VERSION "dbc-export 1 2026.26.6.5"

NS_ :

BS_:

BU_: ADSP APB APP APS APSB BB BMS CC CMP CMPD CP DAS DI DIF DIR DPB EPAS3P EPAS3S EPASTP EPASTS EPBL EPBR ESP EVSE FC GTW HCML HCMR HVP IBST ICR IDB LS OCS1P ODIN PARK PCS PCS2 PLG PM PMF PMR PNCD PTC RADC RCM RCM2 RCM3 RCU SCCM SCM SCS SDCR TAS TCU TCU2 TPMS TRCM UDS UI UIS UMC USM V2G VC VCBATT VCBATT0 VCBATT1 VCBATT2 VCCC VCFRONT VCFRONT1 VCFRONT2 VCLEFT VCRIGHT VCSEAT2L VCSEAT2R VCSEC VEH

BO_ 601 APP_status: 8 APP
 SG_ APP_watchdogState : 0|3@1+ (1,0) [0|6] "" Vector__XXX
 SG_ APP_fusedState : 3|2@1+ (1,0) [0|2] "" Vector__XXX
 SG_ APP_cameraHeaterRequest : 5|1@1+ (1,0) [0|1] "" Vector__XXX
 SG_ APP_factorySummonStatus : 6|4@1+ (1,0) [1|15] "" Vector__XXX
 SG_ APP_clipRecordingStatus : 10|3@1+ (1,0) [0|7] "" Vector__XXX
 SG_ APP_allowApActivationWithBrake : 13|1@1+ (1,0) [0|1] "" Vector__XXX
 SG_ APP_summonUnavailableReason : 14|5@1+ (1,0) [0|31] "" Vector__XXX
 SG_ APP_fsdSuspendState : 19|2@1+ (1,0) [0|2] "" Vector__XXX
 SG_ APP_fsdRevokeStrikeoutCount : 21|3@1+ (1,0) [0|6] "" Vector__XXX
 SG_ APP_teslaVisionSupported : 24|2@1+ (1,0) [0|2] "" Vector__XXX
 SG_ APP_teslaVisionUnsupportedReason : 26|3@1+ (1,0) [0|7] "" Vector__XXX
 SG_ APP_fsdRevokeCount : 29|3@1+ (1,0) [0|6] "" Vector__XXX
 SG_ APP_excessiveAccelPedalWarning : 32|1@1+ (1,0) [0|1] "" Vector__XXX
 SG_ APP_unifiedObjectStackSupported : 33|2@1+ (1,0) [0|2] "" Vector__XXX
 SG_ APP_sendingBUCStream : 35|1@1+ (1,0) [0|1] "" Vector__XXX
 SG_ APP_DDAWSystemStatus : 37|3@1+ (1,0) [0|7] "" Vector__XXX
 SG_ APP_socOperatingMode : 40|2@1+ (1,0) [0|3] "" Vector__XXX
 SG_ APP_summonVersionIdentifier : 42|2@1+ (1,0) [0|3] "" Vector__XXX
 SG_ APP_sentryState : 44|3@1+ (1,0) [0|7] "" Vector__XXX
 SG_ APP_autoparkVersionIdentifier : 47|2@1+ (1,0) [0|3] "" Vector__XXX
 SG_ APP_autonomySystemHealth : 49|1@1+ (1,0) [0|1] "" Vector__XXX
 SG_ APP_uiEthFailoverDisabled : 50|1@1+ (1,0) [0|1] "" Vector__XXX
 SG_ APP_suspendResumeAvailable : 51|1@1+ (1,0) [0|1] "" Vector__XXX
 SG_ APP_statusCounter : 52|4@1+ (1,0) [0|15] "" Vector__XXX
 SG_ APP_statusChecksum : 56|8@1+ (1,0) [0|255] "" Vector__XXX

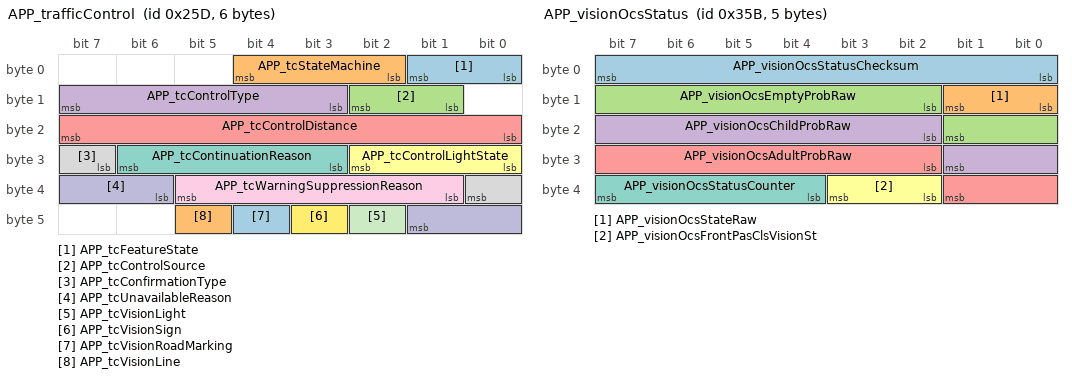
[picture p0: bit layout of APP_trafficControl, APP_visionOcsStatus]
BO_ 605 APP_trafficControl: 6 APP
 SG_ APP_tcFeatureState : 0|2@1+ (1,0) [0|3] "" Vector__XXX
 SG_ APP_tcStateMachine : 2|3@1+ (1,0) [0|7] "" Vector__XXX
 SG_ APP_tcControlSource : 9|2@1+ (1,0) [0|3] "" Vector__XXX
 SG_ APP_tcControlType : 11|5@1+ (1,0) [0|31] "" Vector__XXX
 SG_ APP_tcControlDistance : 16|8@1+ (1,0) [0|254] "m" Vector__XXX
 SG_ APP_tcControlLightState : 24|3@1+ (1,0) [0|7] "" Vector__XXX
 SG_ APP_tcContinuationReason : 27|4@1+ (1,0) [0|15] "" Vector__XXX
 SG_ APP_tcConfirmationType : 31|2@1+ (1,0) [0|3] "" Vector__XXX
 SG_ APP_tcWarningSuppressionReason : 33|5@1+ (1,0) [0|31] "" Vector__XXX
 SG_ APP_tcUnavailableReason : 38|4@1+ (1,0) [0|15] "" Vector__XXX
 SG_ APP_tcVisionLight : 42|1@1+ (1,0) [0|1] "" Vector__XXX
 SG_ APP_tcVisionSign : 43|1@1+ (1,0) [0|1] "" Vector__XXX
 SG_ APP_tcVisionRoadMarking : 44|1@1+ (1,0) [0|1] "" Vector__XXX
 SG_ APP_tcVisionLine : 45|1@1+ (1,0) [0|1] "" Vector__XXX

BO_ 859 APP_visionOcsStatus: 5 APP
 SG_ APP_visionOcsStatusChecksum : 0|8@1+ (1,0) [0|255] "" Vector__XXX
 SG_ APP_visionOcsStateRaw : 8|2@1+ (1,0) [0|3] "" Vector__XXX
 SG_ APP_visionOcsEmptyProbRaw : 10|8@1+ (0.004,0) [0|1.016] "points" Vector__XXX
 SG_ APP_visionOcsChildProbRaw : 18|8@1+ (0.004,0) [0|1.016] "points" Vector__XXX
 SG_ APP_visionOcsAdultProbRaw : 26|8@1+ (0.004,0) [0|1.016] "points" Vector__XXX
 SG_ APP_visionOcsFrontPasClsVisionSt : 34|2@1+ (1,0) [0|3] "" Vector__XXX
 SG_ APP_visionOcsStatusCounter : 36|4@1+ (1,0) [0|15] "" Vector__XXX

BO_ 809 APP_warningMatrix0: 8 APP
 SG_ APP_w001_DEPRECATED : 0|1@1+ (1,0) [0|1] "" Vector__XXX
 SG_ APP_w002_ldwDisabled : 1|1@1+ (1,0) [0|1] "" Vector__XXX
 SG_ APP_w003_isaDisabled : 2|1@1+ (1,0) [0|1] "" Vector__XXX
 SG_ APP_w004_accDisabled : 3|1@1+ (1,0) [0|1] "" Vector__XXX
 SG_ APP_w005_fcwCancelled : 4|1@1+ (1,0) [0|1] "" Vector__XXX
 SG_ APP_w006_aebCancelled : 5|1@1+ (1,0) [0|1] "" Vector__XXX
 SG_ APP_w007_ahlbDisabled : 6|1@1+ (1,0) [0|1] "" Vector__XXX
 SG_ APP_w008_parkDisabled : 7|1@1+ (1,0) [0|1] "" Vector__XXX
 SG_ APP_w009_aebFault : 8|1@1+ (1,0) [0|1] "" Vector__XXX
 SG_ APP_w010_radcCalibIssue : 9|1@1+ (1,0) [0|1] "" Vector__XXX
 SG_ APP_w011_scaEvent : 10|1@1+ (1,0) [0|1] "" Vector__XXX
 SG_ APP_w012_Cam_BootFailure : 11|1@1+ (1,0) [0|1] "" Vector__XXX
 SG_ APP_w013_Cam_Watchdog : 12|1@1+ (1,0) [0|1] "" Vector__XXX
 SG_ APP_w014_swAssert : 13|1@1+ (1,0) [0|1] "" Vector__XXX
 SG_ APP_w015_Camera_Failsafes : 14|1@1+ (1,0) [0|1] "" Vector__XXX
 SG_ APP_w016_aeb_e_event : 15|1@1+ (1,0) [0|1] "" Vector__XXX
 SG_ APP_w017_Cam_Msg_MIA : 16|1@1+ (1,0) [0|1] "" Vector__XXX
 SG_ APP_w018_ECU_Power_Issue : 17|1@1+ (1,0) [0|1] "" Vector__XXX
 SG_ APP_w019_ECU_Stack_Overflow : 18|1@1+ (1,0) [0|1] "" Vector__XXX
 SG_ APP_w020_ECU_checkstopError : 19|1@1+ (1,0) [0|1] "" Vector__XXX
 SG_ APP_w021_ECU_Temperature_Issue : 20|1@1+ (1,0) [0|1] "" Vector__XXX
 SG_ APP_w022_ECU_EEPROM_Failure : 21|1@1+ (1,0) [0|1] "" Vector__XXX
 SG_ APP_w023_ECU_Cam_Statemismatc : 22|1@1+ (1,0) [0|1] "" Vector__XXX
 SG_ APP_w024_ECU_Watchdog_Reset : 23|1@1+ (1,0) [0|1] "" Vector__XXX
 SG_ APP_w025_LC_Steering_Override : 24|1@1+ (1,0) [0|1] "" Vector__XXX
 SG_ APP_w026_ECU_timingIssue : 25|1@1+ (1,0) [0|1] "" Vector__XXX
 SG_ APP_w027_ECU_Reset_Fault : 26|1@1+ (1,0) [0|1] "" Vector__XXX
 SG_ APP_w028_spi_rx_error : 27|1@1+ (1,0) [0|1] "" Vector__XXX
 SG_ APP_w029_spi_tx_error : 28|1@1+ (1,0) [0|1] "" Vector__XXX
 SG_ APP_w030_Heater_Issue : 29|1@1+ (1,0) [0|1] "" Vector__XXX
 SG_ APP_w031_canRxError : 30|1@1+ (1,0) [0|1] "" Vector__XXX
 SG_ APP_w032_canTxError : 31|1@1+ (1,0) [0|1] "" Vector__XXX
 SG_ APP_w033_gtwMia : 32|1@1+ (1,0) [0|1] "" Vector__XXX
 SG_ APP_w034_sccmMia : 33|1@1+ (1,0) [0|1] "" Vector__XXX
 SG_ APP_w035_espMia : 34|1@1+ (1,0) [0|1] "" Vector__XXX
 SG_ APP_w036_bdyMia : 35|1@1+ (1,0) [0|1] "" Vector__XXX
 SG_ APP_w037_camTacIssue : 36|1@1+ (1,0) [0|1] "" Vector__XXX
 SG_ APP_w038_camFailure : 37|1@1+ (1,0) [0|1] "" Vector__XXX
 SG_ APP_w039_sdm_rcm_Mia : 38|1@1+ (1,0) [0|1] "" Vector__XXX
 SG_ APP_w040_autopilotAngleSaturated : 39|1@1+ (1,0) [0|1] "" Vector__XXX
 SG_ APP_w041_autopilotRateSaturated : 40|1@1+ (1,0) [0|1] "" Vector__XXX
 SG_ APP_w042_autopilotAborting : 41|1@1+ (1,0) [0|1] "" Vector__XXX
 SG_ APP_w043_camLongRunTime : 42|1@1+ (1,0) [0|1] "" Vector__XXX
 SG_ APP_w044_appMobileyeFailure : 43|1@1+ (1,0) [0|1] "" Vector__XXX
 SG_ APP_w045_radMia : 44|1@1+ (1,0) [0|1] "" Vector__XXX
 SG_ APP_w046_eepromRecordAbsent : 45|1@1+ (1,0) [0|1] "" Vector__XXX
 SG_ APP_w047_edrEvent : 46|1@1+ (1,0) [0|1] "" Vector__XXX
 SG_ APP_w048_APP_Features_Disabled : 47|1@1+ (1,0) [0|1] "" Vector__XXX
 SG_ APP_w049_eyeqVersionMismatch : 48|1@1+ (1,0) [0|1] "" Vector__XXX
 SG_ APP_w050_aeb_event : 49|1@1+ (1,0) [0|1] "" Vector__XXX
 SG_ APP_w051_radcEcuIssue : 50|1@1+ (1,0) [0|1] "" Vector__XXX
 SG_ APP_w052_radcSensorIssue : 51|1@1+ (1,0) [0|1] "" Vector__XXX
 SG_ APP_w053_radcCommIssue : 52|1@1+ (1,0) [0|1] "" Vector__XXX
 SG_ APP_w054_camAutofix : 53|1@1+ (1,0) [0|1] "" Vector__XXX
 SG_ APP_w055_radcVersionMismatch : 54|1@1+ (1,0) [0|1] "" Vector__XXX
 SG_ APP_w056_diMia : 55|1@1+ (1,0) [0|1] "" Vector__XXX
 SG_ APP_w057_mcuMia : 56|1@1+ (1,0) [0|1] "" Vector__XXX
 SG_ APP_w058_epbMia : 57|1@1+ (1,0) [0|1] "" Vector__XXX
 SG_ APP_w059_parkMia : 58|1@1+ (1,0) [0|1] "" Vector__XXX
 SG_ APP_w060_fcw_event : 59|1@1+ (1,0) [0|1] "" Vector__XXX
 SG_ APP_w061_airSuspensionMia : 60|1@1+ (1,0) [0|1] "" Vector__XXX
 SG_ APP_w062_radcAlignment : 61|1@1+ (1,0) [0|1] "" Vector__XXX
 SG_ APP_w063_parkVersionMismatch : 62|1@1+ (1,0) [0|1] "" Vector__XXX
 SG_ APP_w064_epasMia : 63|1@1+ (1,0) [0|1] "" Vector__XXX

BO_ 873 APP_warningMatrix1: 8 APP
 SG_ APP_w065_deserializerOvercurrent : 0|1@1+ (1,0) [0|1] "" Vector__XXX
 SG_ APP_w066_deserializerLockLost : 1|1@1+ (1,0) [0|1] "" Vector__XXX
 SG_ APP_w067_steeringAlignment : 2|1@1+ (1,0) [0|1] "" Vector__XXX
 SG_ APP_w068_vlInconsistency : 3|1@1+ (1,0) [0|1] "" Vector__XXX
 SG_ APP_w069_apcSpaceMasked : 4|1@1+ (1,0) [0|1] "" Vector__XXX
 SG_ APP_w070_apcIncompleteCal : 5|1@1+ (1,0) [0|1] "" Vector__XXX
 SG_ APP_w071_selfparkStarted : 6|1@1+ (1,0) [0|1] "" Vector__XXX
 SG_ APP_w072_selfparkComplete : 7|1@1+ (1,0) [0|1] "" Vector__XXX
 SG_ APP_w073_issueEscalatedLDW : 8|1@1+ (1,0) [0|1] "" Vector__XXX
 SG_ APP_w074_inPathStationaryObst : 9|1@1+ (1,0) [0|1] "" Vector__XXX
 SG_ APP_w075_scMia : 10|1@1+ (1,0) [0|1] "" Vector__XXX
 SG_ APP_w076_mobilEyeSetC : 11|1@1+ (1,0) [0|1] "" Vector__XXX
 SG_ APP_w077_pmmActive : 12|1@1+ (1,0) [0|1] "" Vector__XXX
 SG_ APP_w078_pmmActive2 : 13|1@1+ (1,0) [0|1] "" Vector__XXX
 SG_ APP_w079_edrAvailable : 14|1@1+ (1,0) [0|1] "" Vector__XXX
 SG_ APP_w080_accFailedActivation : 15|1@1+ (1,0) [0|1] "" Vector__XXX
 SG_ APP_w081_pmmActiveBraking : 16|1@1+ (1,0) [0|1] "" Vector__XXX
 SG_ APP_w082_inPathFSviolation : 17|1@1+ (1,0) [0|1] "" Vector__XXX
 SG_ APP_w083_inPathRADObject : 18|1@1+ (1,0) [0|1] "" Vector__XXX
 SG_ APP_w084_pmmIPSO : 19|1@1+ (1,0) [0|1] "" Vector__XXX
 SG_ APP_w085_pmmSteering : 20|1@1+ (1,0) [0|1] "" Vector__XXX
 SG_ APP_w086_robCollision : 21|1@1+ (1,0) [0|1] "" Vector__XXX
 SG_ APP_w087_DEPRECATED : 22|1@1+ (1,0) [0|1] "" Vector__XXX
 SG_ APP_w088_DEPRECATED : 23|1@1+ (1,0) [0|1] "" Vector__XXX
 SG_ APP_w089_DEPRECATED : 24|1@1+ (1,0) [0|1] "" Vector__XXX
 SG_ APP_w090_DEPRECATED : 25|1@1+ (1,0) [0|1] "" Vector__XXX
 SG_ APP_w091_DEPRECATED : 26|1@1+ (1,0) [0|1] "" Vector__XXX
 SG_ APP_w092_DEPRECATED : 27|1@1+ (1,0) [0|1] "" Vector__XXX
 SG_ APP_w093_DEPRECATED : 28|1@1+ (1,0) [0|1] "" Vector__XXX
 SG_ APP_w094_DEPRECATED : 29|1@1+ (1,0) [0|1] "" Vector__XXX
 SG_ APP_w095_DEPRECATED : 30|1@1+ (1,0) [0|1] "" Vector__XXX
 SG_ APP_w096_DEPRECATED : 31|1@1+ (1,0) [0|1] "" Vector__XXX
 SG_ APP_w097_DEPRECATED : 32|1@1+ (1,0) [0|1] "" Vector__XXX
 SG_ APP_w098_DEPRECATED : 33|1@1+ (1,0) [0|1] "" Vector__XXX
 SG_ APP_w099_DEPRECATED : 34|1@1+ (1,0) [0|1] "" Vector__XXX
 SG_ APP_w100_DEPRECATED : 35|1@1+ (1,0) [0|1] "" Vector__XXX
 SG_ APP_w101_DEPRECATED : 36|1@1+ (1,0) [0|1] "" Vector__XXX
 SG_ APP_w102_DEPRECATED : 37|1@1+ (1,0) [0|1] "" Vector__XXX
 SG_ APP_w103_robExperimentalAEB : 38|1@1+ (1,0) [0|1] "" Vector__XXX
 SG_ APP_w104_DEPRECATED : 39|1@1+ (1,0) [0|1] "" Vector__XXX
 SG_ APP_w105_DEPRECATED : 40|1@1+ (1,0) [0|1] "" Vector__XXX
 SG_ APP_w106_torsionBarOffset : 41|1@1+ (1,0) [0|1] "" Vector__XXX

BO_ 1065 APP_warningMatrix2: 8 APP
 SG_ APP_w129_mainCamExtNotCal : 0|1@1+ (1,0) [0|1] "" Vector__XXX
 SG_ APP_w130_narrowCamExtNotCal : 1|1@1+ (1,0) [0|1] "" Vector__XXX
 SG_ APP_w131_mainCamCalSaved : 2|1@1+ (1,0) [0|1] "" Vector__XXX
 SG_ APP_w132_narrowCamCalSaved : 3|1@1+ (1,0) [0|1] "" Vector__XXX
 SG_ APP_w133_mainCamInitFault : 4|1@1+ (1,0) [0|1] "" Vector__XXX
 SG_ APP_w134_narrowCamInitFault : 5|1@1+ (1,0) [0|1] "" Vector__XXX
 SG_ APP_w135_fisheyeCamInitFault : 6|1@1+ (1,0) [0|1] "" Vector__XXX
 SG_ APP_w136_lPillarCamInitFault : 7|1@1+ (1,0) [0|1] "" Vector__XXX
 SG_ APP_w137_rPillarCamInitFault : 8|1@1+ (1,0) [0|1] "" Vector__XXX
 SG_ APP_w138_lRepeatCamInitFault : 9|1@1+ (1,0) [0|1] "" Vector__XXX
 SG_ APP_w139_rRepeatCamInitFault : 10|1@1+ (1,0) [0|1] "" Vector__XXX
 SG_ APP_w140_backupCamInitFault : 11|1@1+ (1,0) [0|1] "" Vector__XXX
 SG_ APP_w141_ECU_Thermal_Issue : 12|1@1+ (1,0) [0|1] "" Vector__XXX
 SG_ APP_w142_fwdCamPitchProblem : 13|1@1+ (1,0) [0|1] "" Vector__XXX
 SG_ APP_w143_IDF_event : 14|1@1+ (1,0) [0|1] "" Vector__XXX
 SG_ APP_w144_fanctrldError : 15|1@1+ (1,0) [0|1] "" Vector__XXX
 SG_ APP_w145_camSelfCalIssue : 16|1@1+ (1,0) [0|1] "" Vector__XXX
 SG_ APP_w146_telemetryProblem : 17|1@1+ (1,0) [0|1] "" Vector__XXX
 SG_ APP_w147_selfieCamInitFault : 18|1@1+ (1,0) [0|1] "" Vector__XXX
 SG_ APP_w148_overlayActive : 19|1@1+ (1,0) [0|1] "" Vector__XXX
 SG_ APP_w149_diskFull : 20|1@1+ (1,0) [0|1] "" Vector__XXX
 SG_ APP_w150_diMiaPartyBus : 21|1@1+ (1,0) [0|1] "" Vector__XXX
 SG_ APP_w151_epasMiaPartyBus : 22|1@1+ (1,0) [0|1] "" Vector__XXX
 SG_ APP_w152_espMiaPartyBus : 23|1@1+ (1,0) [0|1] "" Vector__XXX
 SG_ APP_w153_rcmMiaPartyBus : 24|1@1+ (1,0) [0|1] "" Vector__XXX
 SG_ APP_w154_vcleftMiaPartyBus : 25|1@1+ (1,0) [0|1] "" Vector__XXX
 SG_ APP_w155_vcrightMiaPartyBus : 26|1@1+ (1,0) [0|1] "" Vector__XXX
 SG_ APP_w156_epblMiaVehBus : 27|1@1+ (1,0) [0|1] "" Vector__XXX
 SG_ APP_w157_sccmMiaVehBus : 28|1@1+ (1,0) [0|1] "" Vector__XXX
 SG_ APP_w158_vcfrontMiaVehBus : 29|1@1+ (1,0) [0|1] "" Vector__XXX
 SG_ APP_w159_vcleftMiaVehBus : 30|1@1+ (1,0) [0|1] "" Vector__XXX
 SG_ APP_w160_vcrightMiaVehBus : 31|1@1+ (1,0) [0|1] "" Vector__XXX
 SG_ APP_w161_backupCameraUnavailable : 32|1@1+ (1,0) [0|1] "" Vector__XXX
 SG_ APP_w162_mainCameraTypeError : 33|1@1+ (1,0) [0|1] "" Vector__XXX
 SG_ APP_w163_narrowCameraTypeError : 34|1@1+ (1,0) [0|1] "" Vector__XXX
 SG_ APP_w164_fisheyeCameraTypeError : 35|1@1+ (1,0) [0|1] "" Vector__XXX
 SG_ APP_w165_lPillarCameraTypeError : 36|1@1+ (1,0) [0|1] "" Vector__XXX
 SG_ APP_w166_rPillarCameraTypeError : 37|1@1+ (1,0) [0|1] "" Vector__XXX
 SG_ APP_w167_lRepeatCameraTypeError : 38|1@1+ (1,0) [0|1] "" Vector__XXX
 SG_ APP_w168_rRepeatCameraTypeError : 39|1@1+ (1,0) [0|1] "" Vector__XXX
 SG_ APP_w169_backupCameraTypeError : 40|1@1+ (1,0) [0|1] "" Vector__XXX
 SG_ APP_w170_selfieCameraTypeError : 41|1@1+ (1,0) [0|1] "" Vector__XXX
 SG_ APP_w171_appHighCoolantFlowReq : 42|1@1+ (1,0) [0|1] "" Vector__XXX
 SG_ APP_w172_fisheyeCamExtNotCal : 43|1@1+ (1,0) [0|1] "" Vector__XXX
 SG_ APP_w173_lPillarCamExtNotCal : 44|1@1+ (1,0) [0|1] "" Vector__XXX
 SG_ APP_w174_rPillarCamExtNotCal : 45|1@1+ (1,0) [0|1] "" Vector__XXX
 SG_ APP_w175_lRepeatCamExtNotCal : 46|1@1+ (1,0) [0|1] "" Vector__XXX
 SG_ APP_w176_rRepeatCamExtNotCal : 47|1@1+ (1,0) [0|1] "" Vector__XXX
 SG_ APP_w177_fisheyeCamCalSaved : 48|1@1+ (1,0) [0|1] "" Vector__XXX
 SG_ APP_w178_lPillarCamCalSaved : 49|1@1+ (1,0) [0|1] "" Vector__XXX
 SG_ APP_w179_rPillarCamCalSaved : 50|1@1+ (1,0) [0|1] "" Vector__XXX
 SG_ APP_w180_lRepeatCamCalSaved : 51|1@1+ (1,0) [0|1] "" Vector__XXX
 SG_ APP_w181_rRepeatCamCalSaved : 52|1@1+ (1,0) [0|1] "" Vector__XXX
 SG_ APP_w182_mainCameraStreamExit : 53|1@1+ (1,0) [0|1] "" Vector__XXX
 SG_ APP_w183_narrowCameraStreamExit : 54|1@1+ (1,0) [0|1] "" Vector__XXX
 SG_ APP_w184_fisheyeCameraStreamExit : 55|1@1+ (1,0) [0|1] "" Vector__XXX
 SG_ APP_w185_lPillarCameraStreamExit : 56|1@1+ (1,0) [0|1] "" Vector__XXX
 SG_ APP_w186_rPillarCameraStreamExit : 57|1@1+ (1,0) [0|1] "" Vector__XXX
 SG_ APP_w187_lRepeatCameraStreamExit : 58|1@1+ (1,0) [0|1] "" Vector__XXX
 SG_ APP_w188_rRepeatCameraStreamExit : 59|1@1+ (1,0) [0|1] "" Vector__XXX
 SG_ APP_w189_backupCameraStreamExit : 60|1@1+ (1,0) [0|1] "" Vector__XXX
 SG_ APP_w190_selfieCameraStreamExit : 61|1@1+ (1,0) [0|1] "" Vector__XXX
 SG_ APP_w191_autopilotAborting : 62|1@1+ (1,0) [0|1] "" Vector__XXX
 SG_ APP_w192_emergencySpeakerFail : 63|1@1+ (1,0) [0|1] "" Vector__XXX

BO_ 1081 APP_warningMatrix3: 8 APP
 SG_ APP_w193_camWindshieldUnclean : 0|1@1+ (1,0) [0|1] "" Vector__XXX
 SG_ APP_w194_accDriverResumeRqrd : 1|1@1+ (1,0) [0|1] "" Vector__XXX
 SG_ APP_w195_scwUnavailable : 2|1@1+ (1,0) [0|1] "" Vector__XXX
 SG_ APP_w196_stopSignWarning : 3|1@1+ (1,0) [0|1] "" Vector__XXX
 SG_ APP_w197_redLightWarning : 4|1@1+ (1,0) [0|1] "" Vector__XXX
 SG_ APP_w198_tsrUnavailable : 5|1@1+ (1,0) [0|1] "" Vector__XXX
 SG_ APP_w199_apcAbort : 6|1@1+ (1,0) [0|1] "" Vector__XXX
 SG_ APP_w200_lcSlowdown : 7|1@1+ (1,0) [0|1] "" Vector__XXX
 SG_ APP_w201_lcAborting : 8|1@1+ (1,0) [0|1] "" Vector__XXX
 SG_ APP_w202_scwNoisyEnvironment : 9|1@1+ (1,0) [0|1] "" Vector__XXX
 SG_ APP_w203_apcActivation : 10|1@1+ (1,0) [0|1] "" Vector__XXX
 SG_ APP_w204_apcFinalFront : 11|1@1+ (1,0) [0|1] "" Vector__XXX
 SG_ APP_w205_apcFinalRear : 12|1@1+ (1,0) [0|1] "" Vector__XXX
 SG_ APP_w206_autosteerNotEnabled : 13|1@1+ (1,0) [0|1] "" Vector__XXX
 SG_ APP_w207_autosteerUnavailable : 14|1@1+ (1,0) [0|1] "" Vector__XXX
 SG_ APP_w208_rackDetected : 15|1@1+ (1,0) [0|1] "" Vector__XXX
 SG_ APP_w209_autoSummonRequest : 16|1@1+ (1,0) [0|1] "" Vector__XXX
 SG_ APP_w210_camObstrcted : 17|1@1+ (1,0) [0|1] "" Vector__XXX
 SG_ APP_w211_accNoSeatBelt : 18|1@1+ (1,0) [0|1] "" Vector__XXX
 SG_ APP_w212_lcUnavailableStrikeOut : 19|1@1+ (1,0) [0|1] "" Vector__XXX
 SG_ APP_w213_autosteerStruckOut : 20|1@1+ (1,0) [0|1] "" Vector__XXX
 SG_ APP_w214_driverNotIntracting : 21|1@1+ (1,0) [0|1] "" Vector__XXX
 SG_ APP_w215_contDriverNotIntracting : 22|1@1+ (1,0) [0|1] "" Vector__XXX
 SG_ APP_w216_driverOverriding : 23|1@1+ (1,0) [0|1] "" Vector__XXX
 SG_ APP_w217_lcUnavailableSpeeding : 24|1@1+ (1,0) [0|1] "" Vector__XXX
 SG_ APP_w218_lcSpeedExceededLimit : 25|1@1+ (1,0) [0|1] "" Vector__XXX
 SG_ APP_w219_lcTempUnavailableSpeed : 26|1@1+ (1,0) [0|1] "" Vector__XXX
 SG_ APP_w220_lcTempUnavailableRoad : 27|1@1+ (1,0) [0|1] "" Vector__XXX
 SG_ APP_w221_accRadarBlind : 28|1@1+ (1,0) [0|1] "" Vector__XXX
 SG_ APP_w222_accCameraBlind : 29|1@1+ (1,0) [0|1] "" Vector__XXX
 SG_ APP_w223_accObjectInPath : 30|1@1+ (1,0) [0|1] "" Vector__XXX
 SG_ APP_w224_accCameraCalibration : 31|1@1+ (1,0) [0|1] "" Vector__XXX
 SG_ APP_w225_lcDegradedVisSpeedLmt : 32|1@1+ (1,0) [0|1] "" Vector__XXX
 SG_ APP_w226_lcCamCalNeededSpeedLmt : 33|1@1+ (1,0) [0|1] "" Vector__XXX
 SG_ APP_w227_virtualWallBlocked : 34|1@1+ (1,0) [0|1] "" Vector__XXX
 SG_ APP_w228_DEPRECATED : 35|1@1+ (1,0) [0|1] "" Vector__XXX
 SG_ APP_w229_alcUltrasoundDamaged : 36|1@1+ (1,0) [0|1] "" Vector__XXX
 SG_ APP_w230_alcUltrasoundBlocked : 37|1@1+ (1,0) [0|1] "" Vector__XXX
 SG_ APP_w231_idfEvent : 38|1@1+ (1,0) [0|1] "" Vector__XXX
 SG_ APP_w232_laneChangeRequested : 39|1@1+ (1,0) [0|1] "" Vector__XXX
 SG_ APP_w233_fsdQuizRequired : 40|1@1+ (1,0) [0|1] "" Vector__XXX
 SG_ APP_w234_activeSafetyTelemetry : 41|1@1+ (1,0) [0|1] "" Vector__XXX
 SG_ APP_w235_fsdRegionNotAllowed : 42|1@1+ (1,0) [0|1] "" Vector__XXX

BO_ 1097 APP_warningMatrix4: 8 APP
 SG_ APP_w257_brakeJerkEvent : 0|1@1+ (1,0) [0|1] "" Vector__XXX
 SG_ APP_w258_aebEvent : 1|1@1+ (1,0) [0|1] "" Vector__XXX
 SG_ APP_w259_aebOverrideEvent : 2|1@1+ (1,0) [0|1] "" Vector__XXX
 SG_ APP_w260_collisionWarningEvent : 3|1@1+ (1,0) [0|1] "" Vector__XXX
 SG_ APP_w261_pcieHardwareErrors : 4|1@1+ (1,0) [0|1] "" Vector__XXX
 SG_ APP_w262_apeCalibMode : 5|1@1+ (1,0) [0|1] "" Vector__XXX
 SG_ APP_w263_lssAbort : 6|1@1+ (1,0) [0|1] "" Vector__XXX
 SG_ APP_w264_lssFault : 7|1@1+ (1,0) [0|1] "" Vector__XXX
 SG_ APP_w265_drvOnNavUnavailable : 8|1@1+ (1,0) [0|1] "" Vector__XXX
 SG_ APP_w266_visionScheduleFallback : 9|1@1+ (1,0) [0|1] "" Vector__XXX
 SG_ APP_w267_benchtopEcu : 10|1@1+ (1,0) [0|1] "" Vector__XXX
 SG_ APP_w268_backupCamExtNotCal : 11|1@1+ (1,0) [0|1] "" Vector__XXX
 SG_ APP_w269_autopilotLimited : 12|1@1+ (1,0) [0|1] "" Vector__XXX
 SG_ APP_w270_blindspotRestricted : 13|1@1+ (1,0) [0|1] "" Vector__XXX
 SG_ APP_w271_laneChangeAborted : 14|1@1+ (1,0) [0|1] "" Vector__XXX
 SG_ APP_w272_laneChangeUnavailable : 15|1@1+ (1,0) [0|1] "" Vector__XXX
 SG_ APP_w273_lssEvent : 16|1@1+ (1,0) [0|1] "" Vector__XXX
 SG_ APP_w274_mainCameraStreamErr : 17|1@1+ (1,0) [0|1] "" Vector__XXX
 SG_ APP_w275_narrowCameraStreamErr : 18|1@1+ (1,0) [0|1] "" Vector__XXX
 SG_ APP_w276_fisheyeCameraStreamErr : 19|1@1+ (1,0) [0|1] "" Vector__XXX
 SG_ APP_w277_lPillarCameraStreamErr : 20|1@1+ (1,0) [0|1] "" Vector__XXX
 SG_ APP_w278_rPillarCameraStreamErr : 21|1@1+ (1,0) [0|1] "" Vector__XXX
 SG_ APP_w279_lRepeatCameraStreamErr : 22|1@1+ (1,0) [0|1] "" Vector__XXX
 SG_ APP_w280_rRepeatCameraStreamErr : 23|1@1+ (1,0) [0|1] "" Vector__XXX
 SG_ APP_w281_backupCameraStreamErr : 24|1@1+ (1,0) [0|1] "" Vector__XXX
 SG_ APP_w282_selfieCameraStreamErr : 25|1@1+ (1,0) [0|1] "" Vector__XXX
 SG_ APP_w283_enhancedSummonAbort : 26|1@1+ (1,0) [0|1] "" Vector__XXX
 SG_ APP_w284_gpsAntennaDisconnected : 27|1@1+ (1,0) [0|1] "" Vector__XXX
 SG_ APP_w285_gpsFaultReset : 28|1@1+ (1,0) [0|1] "" Vector__XXX
 SG_ APP_w286_gpsComIssue : 29|1@1+ (1,0) [0|1] "" Vector__XXX
 SG_ APP_w287_gpsFusionStatus : 30|1@1+ (1,0) [0|1] "" Vector__XXX
 SG_ APP_w288_trafficLightWarning : 31|1@1+ (1,0) [0|1] "" Vector__XXX
 SG_ APP_w289_dramCorrEccErrors : 32|1@1+ (1,0) [0|1] "" Vector__XXX
 SG_ APP_w290_dramUncorrEccErrors : 33|1@1+ (1,0) [0|1] "" Vector__XXX
 SG_ APP_w291_stopSignWarning : 34|1@1+ (1,0) [0|1] "" Vector__XXX
 SG_ APP_w293_mainCameraSyncFailed : 36|1@1+ (1,0) [0|1] "" Vector__XXX
 SG_ APP_w294_narrowCameraSyncFailed : 37|1@1+ (1,0) [0|1] "" Vector__XXX
 SG_ APP_w295_fisheyeCameraSyncFailed : 38|1@1+ (1,0) [0|1] "" Vector__XXX
 SG_ APP_w296_lPillarCameraSyncFailed : 39|1@1+ (1,0) [0|1] "" Vector__XXX
 SG_ APP_w297_rPillarCameraSyncFailed : 40|1@1+ (1,0) [0|1] "" Vector__XXX
 SG_ APP_w298_lRepeatCameraSyncFailed : 41|1@1+ (1,0) [0|1] "" Vector__XXX
 SG_ APP_w299_rRepeatCameraSyncFailed : 42|1@1+ (1,0) [0|1] "" Vector__XXX
 SG_ APP_w300_backupCameraSyncFailed : 43|1@1+ (1,0) [0|1] "" Vector__XXX
 SG_ APP_w301_selfieCameraSyncFailed : 44|1@1+ (1,0) [0|1] "" Vector__XXX
 SG_ APP_w302_vcfrontMiaPartyBus : 45|1@1+ (1,0) [0|1] "" Vector__XXX
 SG_ APP_w303_imuIrational : 46|1@1+ (1,0) [0|1] "" Vector__XXX
 SG_ APP_w304_lssCamBlockedStatus : 47|1@1+ (1,0) [0|1] "" Vector__XXX
 SG_ APP_w305_lssCamStreamExit : 48|1@1+ (1,0) [0|1] "" Vector__XXX
 SG_ APP_w306_lssUltrasonicsBlocked : 49|1@1+ (1,0) [0|1] "" Vector__XXX
 SG_ APP_w307_lssTurnSignalFault : 50|1@1+ (1,0) [0|1] "" Vector__XXX
 SG_ APP_w308_iboosterMia : 51|1@1+ (1,0) [0|1] "" Vector__XXX
 SG_ APP_w309_selfieDisabledOnCar : 52|1@1+ (1,0) [0|1] "" Vector__XXX
 SG_ APP_w310_eth0FrameErrors : 53|1@1+ (1,0) [0|1] "" Vector__XXX
 SG_ APP_w311_eth1FrameErrors : 54|1@1+ (1,0) [0|1] "" Vector__XXX
 SG_ APP_w312_mainCamTypeMismatch : 55|1@1+ (1,0) [0|1] "" Vector__XXX
 SG_ APP_w313_narrowCamTypeMismatch : 56|1@1+ (1,0) [0|1] "" Vector__XXX
 SG_ APP_w314_fisheyeCamTypeMismatch : 57|1@1+ (1,0) [0|1] "" Vector__XXX
 SG_ APP_w315_lPillarCamTypeMismatch : 58|1@1+ (1,0) [0|1] "" Vector__XXX
 SG_ APP_w316_rPillarCamTypeMismatch : 59|1@1+ (1,0) [0|1] "" Vector__XXX
 SG_ APP_w317_lRepeatCamTypeMismatch : 60|1@1+ (1,0) [0|1] "" Vector__XXX
 SG_ APP_w318_rRepeatCamTypeMismatch : 61|1@1+ (1,0) [0|1] "" Vector__XXX
 SG_ APP_w319_backupCamTypeMismatch : 62|1@1+ (1,0) [0|1] "" Vector__XXX
 SG_ APP_w320_selfieCamTypeMismatch : 63|1@1+ (1,0) [0|1] "" Vector__XXX

BO_ 1151 APP_warningMatrix5: 8 APP
 SG_ APP_w321_bmsMia : 0|1@1+ (1,0) [0|1] "" Vector__XXX
 SG_ APP_w322_autoWiperWash : 1|1@1+ (1,0) [0|1] "" Vector__XXX
 SG_ APP_w323_drivableSpaceFCW : 2|1@1+ (1,0) [0|1] "" Vector__XXX
 SG_ APP_w324_adspMia : 3|1@1+ (1,0) [0|1] "" Vector__XXX
 SG_ APP_w325_watchdogReset : 4|1@1+ (1,0) [0|1] "" Vector__XXX
 SG_ APP_w326_kernelPanic : 5|1@1+ (1,0) [0|1] "" Vector__XXX
 SG_ APP_w327_vehicleConfigMismatch : 6|1@1+ (1,0) [0|1] "" Vector__XXX
 SG_ APP_w328_autoparkDegraded : 7|1@1+ (1,0) [0|1] "" Vector__XXX
 SG_ APP_w329_evasiveManeuver : 8|1@1+ (1,0) [0|1] "" Vector__XXX
 SG_ APP_w330_cabinCameraFault : 9|1@1+ (1,0) [0|1] "" Vector__XXX
 SG_ APP_w331_fsdDegradedUnavailable : 10|1@1+ (1,0) [0|1] "" Vector__XXX
 SG_ APP_w332_cameraPositionsSwapped : 11|1@1+ (1,0) [0|1] "" Vector__XXX
 SG_ APP_w333_fsdUnavailableLocation : 12|1@1+ (1,0) [0|1] "" Vector__XXX
 SG_ APP_w334_frontCameraOccluded : 13|1@1+ (1,0) [0|1] "" Vector__XXX
 SG_ APP_w335_tradfcRfSensorError : 14|1@1+ (1,0) [0|1] "" Vector__XXX
 SG_ APP_w336_tradfcLfPmicError : 15|1@1+ (1,0) [0|1] "" Vector__XXX
 SG_ APP_w337_tradfcRfPmicError : 16|1@1+ (1,0) [0|1] "" Vector__XXX
 SG_ APP_w338_tradfcLfTempError : 17|1@1+ (1,0) [0|1] "" Vector__XXX
 SG_ APP_w339_tradfcRfTempError : 18|1@1+ (1,0) [0|1] "" Vector__XXX
 SG_ APP_w340_tradfcCsiError : 19|1@1+ (1,0) [0|1] "" Vector__XXX
 SG_ APP_w341_tradfcCalibError : 20|1@1+ (1,0) [0|1] "" Vector__XXX
 SG_ APP_w342_tradfcDspHwError : 21|1@1+ (1,0) [0|1] "" Vector__XXX
 SG_ APP_w343_tradfcDspSwError : 22|1@1+ (1,0) [0|1] "" Vector__XXX
 SG_ APP_w344_tradfcDspAlgoTimeout : 23|1@1+ (1,0) [0|1] "" Vector__XXX
 SG_ APP_w345_tradfcPerfDegraded : 24|1@1+ (1,0) [0|1] "" Vector__XXX
 SG_ APP_w346_gpsSwEvent : 25|1@1+ (1,0) [0|1] "" Vector__XXX
 SG_ APP_w347_vcbattMiaVehBus : 26|1@1+ (1,0) [0|1] "" Vector__XXX
 SG_ APP_w348_cameraSwUpdateRequired : 27|1@1+ (1,0) [0|1] "" Vector__XXX
 SG_ APP_w349_cameraPersistentlyFault : 28|1@1+ (1,0) [0|1] "" Vector__XXX
 SG_ APP_w350_tradfcSensorMisaligned : 29|1@1+ (1,0) [0|1] "" Vector__XXX
 SG_ APP_w351_csiDevice0Down : 30|1@1+ (1,0) [0|1] "" Vector__XXX
 SG_ APP_w352_csiDevice1Down : 31|1@1+ (1,0) [0|1] "" Vector__XXX
 SG_ APP_w353_csiDevice2Down : 32|1@1+ (1,0) [0|1] "" Vector__XXX
 SG_ APP_w354_tradfcMia : 33|1@1+ (1,0) [0|1] "" Vector__XXX
 SG_ APP_w355_camQuadPowerFault : 34|1@1+ (1,0) [0|1] "" Vector__XXX
 SG_ APP_w356_driverOverriding : 35|1@1+ (1,0) [0|1] "" Vector__XXX
 SG_ APP_w357_ddawSystemFault : 36|1@1+ (1,0) [0|1] "" Vector__XXX
 SG_ APP_w358_isaSystemFault : 37|1@1+ (1,0) [0|1] "" Vector__XXX
 SG_ APP_w359_aebDegraded : 38|1@1+ (1,0) [0|1] "" Vector__XXX
 SG_ APP_w360_apImuNoiseDetected : 39|1@1+ (1,0) [0|1] "" Vector__XXX
 SG_ APP_w361_cabinCameraLEDFault : 40|1@1+ (1,0) [0|1] "" Vector__XXX
 SG_ APP_w362_fasciaCamInitFault : 41|1@1+ (1,0) [0|1] "" Vector__XXX
 SG_ APP_w363_fasciaCameraStreamExit : 42|1@1+ (1,0) [0|1] "" Vector__XXX
 SG_ APP_w364_fasciaCameraTypeError : 43|1@1+ (1,0) [0|1] "" Vector__XXX
 SG_ APP_w365_fasciaCamExtNotCal : 44|1@1+ (1,0) [0|1] "" Vector__XXX
 SG_ APP_w366_fasciaCameraSyncFailed : 45|1@1+ (1,0) [0|1] "" Vector__XXX
 SG_ APP_w367_fasciaCamCalSaved : 46|1@1+ (1,0) [0|1] "" Vector__XXX
 SG_ APP_w368_fasciaCamTypeMismatch : 47|1@1+ (1,0) [0|1] "" Vector__XXX
 SG_ APP_w369_cruiseWithSingleClick : 48|1@1+ (1,0) [0|1] "" Vector__XXX
 SG_ APP_w370_accApUnavUserSettings : 49|1@1+ (1,0) [0|1] "" Vector__XXX
 SG_ APP_w371_networkLoadingIssue : 50|1@1+ (1,0) [0|1] "" Vector__XXX
 SG_ APP_w372_cabinCameraBlocked : 51|1@1+ (1,0) [0|1] "" Vector__XXX
 SG_ APP_w373_gnssUartError : 52|1@1+ (1,0) [0|1] "" Vector__XXX
 SG_ APP_w374_gnssDataMia : 53|1@1+ (1,0) [0|1] "" Vector__XXX
 SG_ APP_w375_gnssPpsMia : 54|1@1+ (1,0) [0|1] "" Vector__XXX
 SG_ APP_w376_wheeltickCountMia : 55|1@1+ (1,0) [0|1] "" Vector__XXX
 SG_ APP_w377_apImuMia : 56|1@1+ (1,0) [0|1] "" Vector__XXX
 SG_ APP_w378_ubloxImuMia : 57|1@1+ (1,0) [0|1] "" Vector__XXX
 SG_ APP_w379_positioningEngineMia : 58|1@1+ (1,0) [0|1] "" Vector__XXX
 SG_ APP_w380_gnssPpsTimestampIssue : 59|1@1+ (1,0) [0|1] "" Vector__XXX
 SG_ APP_w381_apImuTimestampIssue : 60|1@1+ (1,0) [0|1] "" Vector__XXX
 SG_ APP_w382_ubloxImuTimestampIssue : 61|1@1+ (1,0) [0|1] "" Vector__XXX
 SG_ APP_w383_manyApRebootsWhileInP : 62|1@1+ (1,0) [0|1] "" Vector__XXX
 SG_ APP_w384_posEngineInitInMotion : 63|1@1+ (1,0) [0|1] "" Vector__XXX

BO_ 1149 APP_warningMatrix6: 8 APP
 SG_ APP_w385_posEngineUnhealthy : 0|1@1+ (1,0) [0|1] "" Vector__XXX
 SG_ APP_w386_radarOnlyBrakingEvent : 1|1@1+ (1,0) [0|1] "" Vector__XXX
 SG_ APP_w387_radarBlockageDetected : 2|1@1+ (1,0) [0|1] "" Vector__XXX
 SG_ APP_w388_windshieldCameraHeaterF : 3|1@1+ (1,0) [0|1] "" Vector__XXX
 SG_ APP_w389_camFovResidueDetected : 4|1@1+ (1,0) [0|1] "" Vector__XXX
 SG_ APP_w390_cabinCamVisDegraded : 5|1@1+ (1,0) [0|1] "" Vector__XXX
 SG_ APP_w391_cabinCameraBlockedonAP : 6|1@1+ (1,0) [0|1] "" Vector__XXX
 SG_ APP_w392_fsdSuspended : 7|1@1+ (1,0) [0|1] "" Vector__XXX
 SG_ APP_w393_attnMntrUnavailable : 8|1@1+ (1,0) [0|1] "" Vector__XXX
 SG_ APP_w394_apImuGrossErrors : 9|1@1+ (1,0) [0|1] "" Vector__XXX
 SG_ APP_w395_cabinCameraLEDFaultSvc : 10|1@1+ (1,0) [0|1] "" Vector__XXX
 SG_ APP_w396_severeResidueDetected : 11|1@1+ (1,0) [0|1] "" Vector__XXX
 SG_ APP_w397_apFeatDisabledPermanent : 12|1@1+ (1,0) [0|1] "" Vector__XXX
 SG_ APP_w398_imuOutputUnhealthy : 13|1@1+ (1,0) [0|1] "" Vector__XXX
 SG_ APP_w399_brakeboosterMia : 14|1@1+ (1,0) [0|1] "" Vector__XXX
 SG_ APP_w400_selfieCameraFanFault : 15|1@1+ (1,0) [0|1] "" Vector__XXX
 SG_ APP_w401_leftPillarCameraHeaterF : 16|1@1+ (1,0) [0|1] "" Vector__XXX
 SG_ APP_w402_rightPillarCameraHeater : 17|1@1+ (1,0) [0|1] "" Vector__XXX
 SG_ APP_w403_notifyCameraSelfCleanAc : 18|1@1+ (1,0) [0|1] "" Vector__XXX
 SG_ APP_w404_epbrMiaVehBus : 19|1@1+ (1,0) [0|1] "" Vector__XXX
 SG_ APP_w405_apsMia : 20|1@1+ (1,0) [0|1] "" Vector__XXX
 SG_ APP_w406_gnssHWHealthDegraded : 21|1@1+ (1,0) [0|1] "" Vector__XXX
 SG_ APP_w407_autonomyDegraded1 : 22|1@1+ (1,0) [0|1] "" Vector__XXX
 SG_ APP_w408_autonomyDegraded2 : 23|1@1+ (1,0) [0|1] "" Vector__XXX
 SG_ APP_w409_autonomyDegraded3 : 24|1@1+ (1,0) [0|1] "" Vector__XXX
 SG_ APP_w410_autonomyDegraded4 : 25|1@1+ (1,0) [0|1] "" Vector__XXX
 SG_ APP_w411_backupCameraOccluded : 26|1@1+ (1,0) [0|1] "" Vector__XXX
 SG_ APP_w412_abortBackupCamOccluded : 27|1@1+ (1,0) [0|1] "" Vector__XXX
 SG_ APP_w413_autonomyDegraded5 : 28|1@1+ (1,0) [0|1] "" Vector__XXX
 SG_ APP_w415_autonomyUnavailableSyst : 30|1@1+ (1,0) [0|1] "" Vector__XXX
 SG_ APP_w416_autonomyDegradedSystem : 31|1@1+ (1,0) [0|1] "" Vector__XXX
 SG_ APP_w417_autonomyUnavailableVisi : 32|1@1+ (1,0) [0|1] "" Vector__XXX
 SG_ APP_w418_autonomyDegradedVisibil : 33|1@1+ (1,0) [0|1] "" Vector__XXX
 SG_ APP_w419_autonomyUnavailableApSy : 34|1@1+ (1,0) [0|1] "" Vector__XXX
 SG_ APP_w420_autonomyDegradedApSyste : 35|1@1+ (1,0) [0|1] "" Vector__XXX
 SG_ APP_w421_autonomyUnavailableUser : 36|1@1+ (1,0) [0|1] "" Vector__XXX
 SG_ APP_w422_autonomyDegradedUser : 37|1@1+ (1,0) [0|1] "" Vector__XXX
 SG_ APP_w423_cameraVisPopUpForward : 38|1@1+ (1,0) [0|1] "" Vector__XXX
 SG_ APP_w424_cameraVisPopUpLPillar : 39|1@1+ (1,0) [0|1] "" Vector__XXX
 SG_ APP_w425_cameraVisPopUpRPillar : 40|1@1+ (1,0) [0|1] "" Vector__XXX
 SG_ APP_w426_cameraVisPopUpLRepeater : 41|1@1+ (1,0) [0|1] "" Vector__XXX
 SG_ APP_w427_cameraVisPopUpRRepeater : 42|1@1+ (1,0) [0|1] "" Vector__XXX
 SG_ APP_w428_cameraVisPopUpBackup : 43|1@1+ (1,0) [0|1] "" Vector__XXX
 SG_ APP_w429_cameraVisPopUpFascia : 44|1@1+ (1,0) [0|1] "" Vector__XXX
 SG_ APP_w430_frontVisibilityDegraded : 45|1@1+ (1,0) [0|1] "" Vector__XXX
 SG_ APP_w431_frontVisibilityDegraded : 46|1@1+ (1,0) [0|1] "" Vector__XXX
 SG_ APP_w432_frontVisibilityDegraded : 47|1@1+ (1,0) [0|1] "" Vector__XXX
 SG_ APP_w433_leftRepeaterDowngradeDe : 48|1@1+ (1,0) [0|1] "" Vector__XXX
 SG_ APP_w434_rightRepeaterDowngradeD : 49|1@1+ (1,0) [0|1] "" Vector__XXX
 SG_ APP_w435_repeaterAeroRibInfoMism : 50|1@1+ (1,0) [0|1] "" Vector__XXX
 SG_ APP_w436_camCsiError : 51|1@1+ (1,0) [0|1] "" Vector__XXX
 SG_ APP_w437_missingCloudEepromData : 52|1@1+ (1,0) [0|1] "" Vector__XXX
 SG_ APP_w438_rcuMia : 53|1@1+ (1,0) [0|1] "" Vector__XXX
 SG_ APP_w439_ethernetCommFailure : 54|1@1+ (1,0) [0|1] "" Vector__XXX
 SG_ APP_w440_lensHoodOcclusion : 55|1@1+ (1,0) [0|1] "" Vector__XXX
 SG_ APP_w441_cabinCamLEDRailOff : 56|1@1+ (1,0) [0|1] "" Vector__XXX
 SG_ APP_w442_autonomyCancelMethod : 57|1@1+ (1,0) [0|1] "" Vector__XXX
 SG_ APP_w443_mainImagerConfigMismatc : 58|1@1+ (1,0) [0|1] "" Vector__XXX
 SG_ APP_w444_narrowImagerConfigMisma : 59|1@1+ (1,0) [0|1] "" Vector__XXX
 SG_ APP_w445_fisheyeImagerConfigMism : 60|1@1+ (1,0) [0|1] "" Vector__XXX
 SG_ APP_w446_leftPillarImagerConfigM : 61|1@1+ (1,0) [0|1] "" Vector__XXX
 SG_ APP_w447_rightPillarImagerConfig : 62|1@1+ (1,0) [0|1] "" Vector__XXX
 SG_ APP_w448_leftRepeaterImagerConfi : 63|1@1+ (1,0) [0|1] "" Vector__XXX

BO_ 1233 APP_warningMatrix7: 8 APP
 SG_ APP_w449_rightRepeaterImagerConf : 0|1@1+ (1,0) [0|1] "" Vector__XXX
 SG_ APP_w450_backupImagerConfigMisma : 1|1@1+ (1,0) [0|1] "" Vector__XXX
 SG_ APP_w451_fasciaImagerConfigMisma : 2|1@1+ (1,0) [0|1] "" Vector__XXX
 SG_ APP_w452_selfieImagerConfigMisma : 3|1@1+ (1,0) [0|1] "" Vector__XXX
 SG_ APP_w453_driverCancelBlinker : 4|1@1+ (1,0) [0|1] "" Vector__XXX
 SG_ APP_w454_appAutonomySystemUnheal : 5|1@1+ (1,0) [0|1] "" Vector__XXX
 SG_ APP_w455_apbAutonomySystemUnheal : 6|1@1+ (1,0) [0|1] "" Vector__XXX
 SG_ APP_w456_autonomyUnavailableColl : 7|1@1+ (1,0) [0|1] "" Vector__XXX
 SG_ APP_w457_autonomyDegradedCollisi : 8|1@1+ (1,0) [0|1] "" Vector__XXX
 SG_ APP_w458_aceEvent : 9|1@1+ (1,0) [0|1] "" Vector__XXX
 SG_ APP_w459_epbrMiaPartyBus : 10|1@1+ (1,0) [0|1] "" Vector__XXX
 SG_ APP_w460_epblMiaChBus : 11|1@1+ (1,0) [0|1] "" Vector__XXX
 SG_ APP_w461_autonomyReroute : 12|1@1+ (1,0) [0|1] "" Vector__XXX
 SG_ APP_w462_selfDrivingUnavailable : 13|1@1+ (1,0) [0|1] "" Vector__XXX
 SG_ APP_w463_selfDrivingCamObstrcted : 14|1@1+ (1,0) [0|1] "" Vector__XXX
 SG_ APP_w464_autonomyUnavailableODD : 15|1@1+ (1,0) [0|1] "" Vector__XXX
 SG_ APP_w465_autonomyDegradedODD : 16|1@1+ (1,0) [0|1] "" Vector__XXX
 SG_ APP_w466_missingSensorOTP : 17|1@1+ (1,0) [0|1] "" Vector__XXX
 SG_ APP_w467_imuDegraded : 18|1@1+ (1,0) [0|1] "" Vector__XXX
 SG_ APP_w477_driverSeatReclined : 28|1@1+ (1,0) [0|1] "" Vector__XXX
 SG_ APP_w478_runModeSwitch : 29|1@1+ (1,0) [0|1] "" Vector__XXX
 SG_ APP_w482_appVisionFailoverActiva : 33|1@1+ (1,0) [0|1] "" Vector__XXX
 SG_ APP_w483_apbVisionFailoverActiva : 34|1@1+ (1,0) [0|1] "" Vector__XXX

BO_TX_BU_ 601 : APP;
BO_TX_BU_ 605 : APP;
BO_TX_BU_ 859 : APP;
BO_TX_BU_ 809 : APP;
BO_TX_BU_ 873 : APP;
BO_TX_BU_ 1065 : APP;
BO_TX_BU_ 1081 : APP;
BO_TX_BU_ 1097 : APP;
BO_TX_BU_ 1151 : APP;
BO_TX_BU_ 1149 : APP;
BO_TX_BU_ 1233 : APP;
CM_ BO_ 601 "Driver assistance computer (primary) message: status";
CM_ SG_ 601 APP_watchdogState "State of system watchdog on ParkerB; raw 7 = signal not available (SNA)";
CM_ SG_ 601 APP_fusedState "Driver assistance computer (primary): fused state; raw 3 = signal not available (SNA)";
CM_ SG_ 601 APP_cameraHeaterRequest "Indicates if heater grid is active because of request from AP cameras.";
CM_ SG_ 601 APP_factorySummonStatus "Driver assistance computer (primary): factory summon status; raw 0 = signal not available (SNA)";
CM_ SG_ 601 APP_clipRecordingStatus "Driver assistance computer (primary): clip recording status";
CM_ SG_ 601 APP_allowApActivationWithBrake "Indicates whether Autopilot (AP) activation while brake pressed is allowed.";
CM_ SG_ 601 APP_summonUnavailableReason "The reason why smart summon is currently unavailable.";
CM_ SG_ 601 APP_fsdSuspendState "If FSD feature is suspended on this car; raw 3 = signal not available (SNA)";
CM_ SG_ 601 APP_fsdRevokeStrikeoutCount "Reports the number of strikeouts counted towards revoking Full Self-Driving (FSD) feature; raw 7 = signal not available (SNA)";
CM_ SG_ 601 APP_teslaVisionSupported "Whether autopilot can support tesla vision; raw 3 = signal not available (SNA)";
CM_ SG_ 601 APP_teslaVisionUnsupportedReason "Reason for vehicle not supporting tesla vision";
CM_ SG_ 601 APP_fsdRevokeCount "Reports the number of times the car has had Full Self-Driving (FSD) revoked; raw 7 = signal not available (SNA)";
CM_ SG_ 601 APP_excessiveAccelPedalWarning "Indicates that driver is using acceleration pedal continously and excessively";
CM_ SG_ 601 APP_unifiedObjectStackSupported "Whether autopilot can support unified objects stack for tesla vision; raw 3 = signal not available (SNA)";
CM_ SG_ 601 APP_sendingBUCStream "Indicates if the backup camera stream is being sent to the Media Control Unit (MCU) from Turbo A.";
CM_ SG_ 601 APP_DDAWSystemStatus "DDAW system status; raw 4 = signal not available (SNA)";
CM_ SG_ 601 APP_socOperatingMode "Operating Mode of the SOC";
CM_ SG_ 601 APP_summonVersionIdentifier "Driver assistance computer (primary): summon version identifier";
CM_ SG_ 601 APP_sentryState "Reports the Sentry mode state on Gen. 4 Hardware (HW4) and later vehicles; raw 6 = signal not available (SNA)";
CM_ SG_ 601 APP_autoparkVersionIdentifier "Driver assistance computer (primary): autopark version identifier";
CM_ SG_ 601 APP_autonomySystemHealth "Driver assistance computer (primary): autonomy system health";
CM_ SG_ 601 APP_uiEthFailoverDisabled "Driver assistance computer (primary): ui eth failover disabled";
CM_ SG_ 601 APP_suspendResumeAvailable "Driver assistance computer (primary): suspend resume available";
CM_ SG_ 601 APP_statusCounter "Driver assistance computer (primary): status counter";
CM_ SG_ 601 APP_statusChecksum "Driver assistance computer (primary): status checksum";
CM_ BO_ 605 "Driver assistance computer (primary) message: traffic control";
CM_ SG_ 605 APP_tcFeatureState "The feature level state of stopping for traffic controls";
CM_ SG_ 605 APP_tcStateMachine "The traffic control state machine's internal control state.";
CM_ SG_ 605 APP_tcControlSource "The input data source for the traffic control object";
CM_ SG_ 605 APP_tcControlType "The specific type of traffic control, note not all are control worthy.";
CM_ SG_ 605 APP_tcControlDistance "The distance to the nearest critical traffic control object; raw 255 = signal not available (SNA)";
CM_ SG_ 605 APP_tcControlLightState "Driver assistance computer (primary): tc control light state";
CM_ SG_ 605 APP_tcContinuationReason "The reason the traffic control state machine entered the continue state.";
CM_ SG_ 605 APP_tcConfirmationType "The mechanism of how the driver confirmed the traffic control.";
CM_ SG_ 605 APP_tcWarningSuppressionReason "The suppression reason for the traffic control warning feature.";
CM_ SG_ 605 APP_tcUnavailableReason "The reason why the traffic control feature is currently unavailable.";
CM_ SG_ 605 APP_tcVisionLight "Whether or not the traffic light has a vision measurement.";
CM_ SG_ 605 APP_tcVisionSign "Whether or not the traffic sign has a vision measurement.";
CM_ SG_ 605 APP_tcVisionRoadMarking "Whether or not the road marking has a vision measurement.";
CM_ SG_ 605 APP_tcVisionLine "Whether or not the traffic control line has a vision measurement.";
CM_ BO_ 859 "Driver assistance computer (primary) message: vision ocs status";
CM_ SG_ 859 APP_visionOcsStatusChecksum "Driver assistance computer (primary): vision ocs status checksum";
CM_ SG_ 859 APP_visionOcsStateRaw "Reports classification state raw signal for front passenger from interior camera.";
CM_ SG_ 859 APP_visionOcsEmptyProbRaw "Driver assistance computer (primary): vision ocs empty prob raw; raw 255 = signal not available (SNA)";
CM_ SG_ 859 APP_visionOcsChildProbRaw "Driver assistance computer (primary): vision ocs child prob raw; raw 255 = signal not available (SNA)";
CM_ SG_ 859 APP_visionOcsAdultProbRaw "Driver assistance computer (primary): vision ocs adult prob raw; raw 255 = signal not available (SNA)";
CM_ SG_ 859 APP_visionOcsFrontPasClsVisionSt "Reports classification state of front passenger seat after Bayesian filter.";
CM_ SG_ 859 APP_visionOcsStatusCounter "Driver assistance computer (primary): vision ocs status counter";
CM_ BO_ 809 "Driver assistance computer (primary) message: warning matrix0";
CM_ SG_ 809 APP_w001_DEPRECATED "Driver assistance computer (primary): w001 DEPRECATED";
CM_ SG_ 809 APP_w002_ldwDisabled "Driver assistance computer (primary): w002 ldw disabled";
CM_ SG_ 809 APP_w003_isaDisabled "Driver assistance computer (primary): w003 isa disabled";
CM_ SG_ 809 APP_w004_accDisabled "Driver assistance computer (primary): w004 acc disabled";
CM_ SG_ 809 APP_w005_fcwCancelled "Driver assistance computer (primary): w005 fcw cancelled";
CM_ SG_ 809 APP_w006_aebCancelled "Driver assistance computer (primary): w006 aeb cancelled";
CM_ SG_ 809 APP_w007_ahlbDisabled "Driver assistance computer (primary): w007 ahlb disabled";
CM_ SG_ 809 APP_w008_parkDisabled "Driver assistance computer (primary): w008 park disabled";
CM_ SG_ 809 APP_w009_aebFault "Driver assistance computer (primary): w009 aeb fault";
CM_ SG_ 809 APP_w010_radcCalibIssue "Driver assistance computer (primary): w010 radc calib issue";
CM_ SG_ 809 APP_w011_scaEvent "Driver assistance computer (primary): w011 sca event";
CM_ SG_ 809 APP_w012_Cam_BootFailure "Driver assistance computer (primary): w012 cam boot failure";
CM_ SG_ 809 APP_w013_Cam_Watchdog "Driver assistance computer (primary): w013 cam watchdog";
CM_ SG_ 809 APP_w014_swAssert "Driver assistance computer (primary): w014 sw assert";
CM_ SG_ 809 APP_w015_Camera_Failsafes "Driver assistance computer (primary): w015 camera failsafes";
CM_ SG_ 809 APP_w016_aeb_e_event "Driver assistance computer (primary): w016 aeb e event";
CM_ SG_ 809 APP_w017_Cam_Msg_MIA "Driver assistance computer (primary): w017 cam msg MIA";
CM_ SG_ 809 APP_w018_ECU_Power_Issue "Driver assistance computer (primary): w018 ECU power issue";
CM_ SG_ 809 APP_w019_ECU_Stack_Overflow "Driver assistance computer (primary): w019 ECU stack overflow";
CM_ SG_ 809 APP_w020_ECU_checkstopError "Driver assistance computer (primary): w020 ECU checkstop error";
CM_ SG_ 809 APP_w021_ECU_Temperature_Issue "Driver assistance computer (primary): w021 ECU temperature issue";
CM_ SG_ 809 APP_w022_ECU_EEPROM_Failure "Driver assistance computer (primary): w022 ECU EEPROM failure";
CM_ SG_ 809 APP_w023_ECU_Cam_Statemismatc "Driver assistance computer (primary): w023 ECU cam statemismatc";
CM_ SG_ 809 APP_w024_ECU_Watchdog_Reset "Driver assistance computer (primary): w024 ECU watchdog reset";
CM_ SG_ 809 APP_w025_LC_Steering_Override "Driver assistance computer (primary): w025 LC steering override";
CM_ SG_ 809 APP_w026_ECU_timingIssue "Driver assistance computer (primary): w026 ECU timing issue";
CM_ SG_ 809 APP_w027_ECU_Reset_Fault "Driver assistance computer (primary): w027 ECU reset fault";
CM_ SG_ 809 APP_w028_spi_rx_error "Driver assistance computer (primary): w028 spi rx error";
CM_ SG_ 809 APP_w029_spi_tx_error "Driver assistance computer (primary): w029 spi tx error";
CM_ SG_ 809 APP_w030_Heater_Issue "Driver assistance computer (primary): w030 heater issue";
CM_ SG_ 809 APP_w031_canRxError "Driver assistance computer (primary): w031 can rx error";
CM_ SG_ 809 APP_w032_canTxError "Driver assistance computer (primary): w032 can tx error";
CM_ SG_ 809 APP_w033_gtwMia "Driver assistance computer (primary): w033 gtw mia";
CM_ SG_ 809 APP_w034_sccmMia "Driver assistance computer (primary): w034 sccm mia";
CM_ SG_ 809 APP_w035_espMia "Driver assistance computer (primary): w035 esp mia";
CM_ SG_ 809 APP_w036_bdyMia "Driver assistance computer (primary): w036 bdy mia";
CM_ SG_ 809 APP_w037_camTacIssue "Driver assistance computer (primary): w037 cam tac issue";
CM_ SG_ 809 APP_w038_camFailure "Driver assistance computer (primary): w038 cam failure";
CM_ SG_ 809 APP_w039_sdm_rcm_Mia "Driver assistance computer (primary): w039 sdm rcm mia";
CM_ SG_ 809 APP_w040_autopilotAngleSaturated "Driver assistance computer (primary): w040 autopilot angle saturated";
CM_ SG_ 809 APP_w041_autopilotRateSaturated "Driver assistance computer (primary): w041 autopilot rate saturated";
CM_ SG_ 809 APP_w042_autopilotAborting "Driver assistance computer (primary): w042 autopilot aborting";
CM_ SG_ 809 APP_w043_camLongRunTime "Driver assistance computer (primary): w043 cam long run time";
CM_ SG_ 809 APP_w044_appMobileyeFailure "Driver assistance computer (primary): w044 app mobileye failure";
CM_ SG_ 809 APP_w045_radMia "Driver assistance computer (primary): w045 rad mia";
CM_ SG_ 809 APP_w046_eepromRecordAbsent "Driver assistance computer (primary): w046 eeprom record absent";
CM_ SG_ 809 APP_w047_edrEvent "Driver assistance computer (primary): w047 edr event";
CM_ SG_ 809 APP_w048_APP_Features_Disabled "Driver assistance computer (primary): w048 APP features disabled";
CM_ SG_ 809 APP_w049_eyeqVersionMismatch "Driver assistance computer (primary): w049 eyeq version mismatch";
CM_ SG_ 809 APP_w050_aeb_event "Driver assistance computer (primary): w050 aeb event";
CM_ SG_ 809 APP_w051_radcEcuIssue "Driver assistance computer (primary): w051 radc ecu issue";
CM_ SG_ 809 APP_w052_radcSensorIssue "Driver assistance computer (primary): w052 radc sensor issue";
CM_ SG_ 809 APP_w053_radcCommIssue "Driver assistance computer (primary): w053 radc comm issue";
CM_ SG_ 809 APP_w054_camAutofix "Driver assistance computer (primary): w054 cam autofix";
CM_ SG_ 809 APP_w055_radcVersionMismatch "Driver assistance computer (primary): w055 radc version mismatch";
CM_ SG_ 809 APP_w056_diMia "Driver assistance computer (primary): w056 di mia";
CM_ SG_ 809 APP_w057_mcuMia "Driver assistance computer (primary): w057 mcu mia";
CM_ SG_ 809 APP_w058_epbMia "Driver assistance computer (primary): w058 epb mia";
CM_ SG_ 809 APP_w059_parkMia "Driver assistance computer (primary): w059 park mia";
CM_ SG_ 809 APP_w060_fcw_event "Driver assistance computer (primary): w060 fcw event";
CM_ SG_ 809 APP_w061_airSuspensionMia "Driver assistance computer (primary): w061 air suspension mia";
CM_ SG_ 809 APP_w062_radcAlignment "Driver assistance computer (primary): w062 radc alignment";
CM_ SG_ 809 APP_w063_parkVersionMismatch "Driver assistance computer (primary): w063 park version mismatch";
CM_ SG_ 809 APP_w064_epasMia "Driver assistance computer (primary): w064 epas mia";
CM_ BO_ 873 "Driver assistance computer (primary) message: warning matrix1";
CM_ SG_ 873 APP_w065_deserializerOvercurrent "Driver assistance computer (primary): w065 deserializer overcurrent";
CM_ SG_ 873 APP_w066_deserializerLockLost "Driver assistance computer (primary): w066 deserializer lock lost";
CM_ SG_ 873 APP_w067_steeringAlignment "Driver assistance computer (primary): w067 steering alignment";
CM_ SG_ 873 APP_w068_vlInconsistency "Driver assistance computer (primary): w068 vl inconsistency";
CM_ SG_ 873 APP_w069_apcSpaceMasked "Driver assistance computer (primary): w069 apc space masked";
CM_ SG_ 873 APP_w070_apcIncompleteCal "Driver assistance computer (primary): w070 apc incomplete cal";
CM_ SG_ 873 APP_w071_selfparkStarted "Driver assistance computer (primary): w071 selfpark started";
CM_ SG_ 873 APP_w072_selfparkComplete "Driver assistance computer (primary): w072 selfpark complete";
CM_ SG_ 873 APP_w073_issueEscalatedLDW "Driver assistance computer (primary): w073 issue escalated LDW";
CM_ SG_ 873 APP_w074_inPathStationaryObst "Driver assistance computer (primary): w074 in path stationary obst";
CM_ SG_ 873 APP_w075_scMia "Driver assistance computer (primary): w075 sc mia";
CM_ SG_ 873 APP_w076_mobilEyeSetC "Driver assistance computer (primary): w076 mobil eye set c";
CM_ SG_ 873 APP_w077_pmmActive "Driver assistance computer (primary): w077 pmm active";
CM_ SG_ 873 APP_w078_pmmActive2 "Driver assistance computer (primary): w078 pmm active2";
CM_ SG_ 873 APP_w079_edrAvailable "Driver assistance computer (primary): w079 edr available";
CM_ SG_ 873 APP_w080_accFailedActivation "Driver assistance computer (primary): w080 acc failed activation";
CM_ SG_ 873 APP_w081_pmmActiveBraking "Driver assistance computer (primary): w081 pmm active braking";
CM_ SG_ 873 APP_w082_inPathFSviolation "Driver assistance computer (primary): w082 in path f sviolation";
CM_ SG_ 873 APP_w083_inPathRADObject "Driver assistance computer (primary): w083 in path RAD object";
CM_ SG_ 873 APP_w084_pmmIPSO "Driver assistance computer (primary): w084 pmm IPSO";
CM_ SG_ 873 APP_w085_pmmSteering "Driver assistance computer (primary): w085 pmm steering";
CM_ SG_ 873 APP_w086_robCollision "Driver assistance computer (primary): w086 rob collision";
CM_ SG_ 873 APP_w087_DEPRECATED "Driver assistance computer (primary): w087 DEPRECATED";
CM_ SG_ 873 APP_w088_DEPRECATED "Driver assistance computer (primary): w088 DEPRECATED";
CM_ SG_ 873 APP_w089_DEPRECATED "Driver assistance computer (primary): w089 DEPRECATED";
CM_ SG_ 873 APP_w090_DEPRECATED "Driver assistance computer (primary): w090 DEPRECATED";
CM_ SG_ 873 APP_w091_DEPRECATED "Driver assistance computer (primary): w091 DEPRECATED";
CM_ SG_ 873 APP_w092_DEPRECATED "Driver assistance computer (primary): w092 DEPRECATED";
CM_ SG_ 873 APP_w093_DEPRECATED "Driver assistance computer (primary): w093 DEPRECATED";
CM_ SG_ 873 APP_w094_DEPRECATED "Driver assistance computer (primary): w094 DEPRECATED";
CM_ SG_ 873 APP_w095_DEPRECATED "Driver assistance computer (primary): w095 DEPRECATED";
CM_ SG_ 873 APP_w096_DEPRECATED "Driver assistance computer (primary): w096 DEPRECATED";
CM_ SG_ 873 APP_w097_DEPRECATED "Driver assistance computer (primary): w097 DEPRECATED";
CM_ SG_ 873 APP_w098_DEPRECATED "Driver assistance computer (primary): w098 DEPRECATED";
CM_ SG_ 873 APP_w099_DEPRECATED "Driver assistance computer (primary): w099 DEPRECATED";
CM_ SG_ 873 APP_w100_DEPRECATED "Driver assistance computer (primary): w100 DEPRECATED";
CM_ SG_ 873 APP_w101_DEPRECATED "Driver assistance computer (primary): w101 DEPRECATED";
CM_ SG_ 873 APP_w102_DEPRECATED "Driver assistance computer (primary): w102 DEPRECATED";
CM_ SG_ 873 APP_w103_robExperimentalAEB "Driver assistance computer (primary): w103 rob experimental AEB";
CM_ SG_ 873 APP_w104_DEPRECATED "Driver assistance computer (primary): w104 DEPRECATED";
CM_ SG_ 873 APP_w105_DEPRECATED "Driver assistance computer (primary): w105 DEPRECATED";
CM_ SG_ 873 APP_w106_torsionBarOffset "Driver assistance computer (primary): w106 torsion bar offset";
CM_ BO_ 1065 "Driver assistance computer (primary) message: warning matrix2";
CM_ SG_ 1065 APP_w129_mainCamExtNotCal "Driver assistance computer (primary): w129 main cam ext not cal";
CM_ SG_ 1065 APP_w130_narrowCamExtNotCal "Driver assistance computer (primary): w130 narrow cam ext not cal";
CM_ SG_ 1065 APP_w131_mainCamCalSaved "Driver assistance computer (primary): w131 main cam cal saved";
CM_ SG_ 1065 APP_w132_narrowCamCalSaved "Driver assistance computer (primary): w132 narrow cam cal saved";
CM_ SG_ 1065 APP_w133_mainCamInitFault "Driver assistance computer (primary): w133 main cam init fault";
CM_ SG_ 1065 APP_w134_narrowCamInitFault "Driver assistance computer (primary): w134 narrow cam init fault";
CM_ SG_ 1065 APP_w135_fisheyeCamInitFault "Driver assistance computer (primary): w135 fisheye cam init fault";
CM_ SG_ 1065 APP_w136_lPillarCamInitFault "Driver assistance computer (primary): w136 l pillar cam init fault";
CM_ SG_ 1065 APP_w137_rPillarCamInitFault "Driver assistance computer (primary): w137 r pillar cam init fault";
CM_ SG_ 1065 APP_w138_lRepeatCamInitFault "Driver assistance computer (primary): w138 l repeat cam init fault";
CM_ SG_ 1065 APP_w139_rRepeatCamInitFault "Driver assistance computer (primary): w139 r repeat cam init fault";
CM_ SG_ 1065 APP_w140_backupCamInitFault "Driver assistance computer (primary): w140 backup cam init fault";
CM_ SG_ 1065 APP_w141_ECU_Thermal_Issue "Driver assistance computer (primary): w141 ECU thermal issue";
CM_ SG_ 1065 APP_w142_fwdCamPitchProblem "Driver assistance computer (primary): w142 fwd cam pitch problem";
CM_ SG_ 1065 APP_w143_IDF_event "Driver assistance computer (primary): w143 IDF event";
CM_ SG_ 1065 APP_w144_fanctrldError "Driver assistance computer (primary): w144 fanctrld error";
CM_ SG_ 1065 APP_w145_camSelfCalIssue "Driver assistance computer (primary): w145 cam self cal issue";
CM_ SG_ 1065 APP_w146_telemetryProblem "Driver assistance computer (primary): w146 telemetry problem";
CM_ SG_ 1065 APP_w147_selfieCamInitFault "Driver assistance computer (primary): w147 selfie cam init fault";
CM_ SG_ 1065 APP_w148_overlayActive "Driver assistance computer (primary): w148 overlay active";
CM_ SG_ 1065 APP_w149_diskFull "Driver assistance computer (primary): w149 disk full";
CM_ SG_ 1065 APP_w150_diMiaPartyBus "Driver assistance computer (primary): w150 di mia party bus";
CM_ SG_ 1065 APP_w151_epasMiaPartyBus "Driver assistance computer (primary): w151 epas mia party bus";
CM_ SG_ 1065 APP_w152_espMiaPartyBus "Driver assistance computer (primary): w152 esp mia party bus";
CM_ SG_ 1065 APP_w153_rcmMiaPartyBus "Driver assistance computer (primary): w153 rcm mia party bus";
CM_ SG_ 1065 APP_w154_vcleftMiaPartyBus "Driver assistance computer (primary): w154 vcleft mia party bus";
CM_ SG_ 1065 APP_w155_vcrightMiaPartyBus "Driver assistance computer (primary): w155 vcright mia party bus";
CM_ SG_ 1065 APP_w156_epblMiaVehBus "Driver assistance computer (primary): w156 epbl mia veh bus";
CM_ SG_ 1065 APP_w157_sccmMiaVehBus "Driver assistance computer (primary): w157 sccm mia veh bus";
CM_ SG_ 1065 APP_w158_vcfrontMiaVehBus "Driver assistance computer (primary): w158 vcfront mia veh bus";
CM_ SG_ 1065 APP_w159_vcleftMiaVehBus "Driver assistance computer (primary): w159 vcleft mia veh bus";
CM_ SG_ 1065 APP_w160_vcrightMiaVehBus "Driver assistance computer (primary): w160 vcright mia veh bus";
CM_ SG_ 1065 APP_w161_backupCameraUnavailable "Driver assistance computer (primary): w161 backup camera unavailable";
CM_ SG_ 1065 APP_w162_mainCameraTypeError "Driver assistance computer (primary): w162 main camera type error";
CM_ SG_ 1065 APP_w163_narrowCameraTypeError "Driver assistance computer (primary): w163 narrow camera type error";
CM_ SG_ 1065 APP_w164_fisheyeCameraTypeError "Driver assistance computer (primary): w164 fisheye camera type error";
CM_ SG_ 1065 APP_w165_lPillarCameraTypeError "Driver assistance computer (primary): w165 l pillar camera type error";
CM_ SG_ 1065 APP_w166_rPillarCameraTypeError "Driver assistance computer (primary): w166 r pillar camera type error";
CM_ SG_ 1065 APP_w167_lRepeatCameraTypeError "Driver assistance computer (primary): w167 l repeat camera type error";
CM_ SG_ 1065 APP_w168_rRepeatCameraTypeError "Driver assistance computer (primary): w168 r repeat camera type error";
CM_ SG_ 1065 APP_w169_backupCameraTypeError "Driver assistance computer (primary): w169 backup camera type error";
CM_ SG_ 1065 APP_w170_selfieCameraTypeError "Driver assistance computer (primary): w170 selfie camera type error";
CM_ SG_ 1065 APP_w171_appHighCoolantFlowReq "Driver assistance computer (primary): w171 app high coolant flow req";
CM_ SG_ 1065 APP_w172_fisheyeCamExtNotCal "Driver assistance computer (primary): w172 fisheye cam ext not cal";
CM_ SG_ 1065 APP_w173_lPillarCamExtNotCal "Driver assistance computer (primary): w173 l pillar cam ext not cal";
CM_ SG_ 1065 APP_w174_rPillarCamExtNotCal "Driver assistance computer (primary): w174 r pillar cam ext not cal";
CM_ SG_ 1065 APP_w175_lRepeatCamExtNotCal "Driver assistance computer (primary): w175 l repeat cam ext not cal";
CM_ SG_ 1065 APP_w176_rRepeatCamExtNotCal "Driver assistance computer (primary): w176 r repeat cam ext not cal";
CM_ SG_ 1065 APP_w177_fisheyeCamCalSaved "Driver assistance computer (primary): w177 fisheye cam cal saved";
CM_ SG_ 1065 APP_w178_lPillarCamCalSaved "Driver assistance computer (primary): w178 l pillar cam cal saved";
CM_ SG_ 1065 APP_w179_rPillarCamCalSaved "Driver assistance computer (primary): w179 r pillar cam cal saved";
CM_ SG_ 1065 APP_w180_lRepeatCamCalSaved "Driver assistance computer (primary): w180 l repeat cam cal saved";
CM_ SG_ 1065 APP_w181_rRepeatCamCalSaved "Driver assistance computer (primary): w181 r repeat cam cal saved";
CM_ SG_ 1065 APP_w182_mainCameraStreamExit "Driver assistance computer (primary): w182 main camera stream exit";
CM_ SG_ 1065 APP_w183_narrowCameraStreamExit "Driver assistance computer (primary): w183 narrow camera stream exit";
CM_ SG_ 1065 APP_w184_fisheyeCameraStreamExit "Driver assistance computer (primary): w184 fisheye camera stream exit";
CM_ SG_ 1065 APP_w185_lPillarCameraStreamExit "Driver assistance computer (primary): w185 l pillar camera stream exit";
CM_ SG_ 1065 APP_w186_rPillarCameraStreamExit "Driver assistance computer (primary): w186 r pillar camera stream exit";
CM_ SG_ 1065 APP_w187_lRepeatCameraStreamExit "Driver assistance computer (primary): w187 l repeat camera stream exit";
CM_ SG_ 1065 APP_w188_rRepeatCameraStreamExit "Driver assistance computer (primary): w188 r repeat camera stream exit";
CM_ SG_ 1065 APP_w189_backupCameraStreamExit "Driver assistance computer (primary): w189 backup camera stream exit";
CM_ SG_ 1065 APP_w190_selfieCameraStreamExit "Driver assistance computer (primary): w190 selfie camera stream exit";
CM_ SG_ 1065 APP_w191_autopilotAborting "Driver assistance computer (primary): w191 autopilot aborting";
CM_ SG_ 1065 APP_w192_emergencySpeakerFail "Driver assistance computer (primary): w192 emergency speaker fail";
CM_ BO_ 1081 "Driver assistance computer (primary) message: warning matrix3";
CM_ SG_ 1081 APP_w193_camWindshieldUnclean "Driver assistance computer (primary): w193 cam windshield unclean";
CM_ SG_ 1081 APP_w194_accDriverResumeRqrd "Driver assistance computer (primary): w194 acc driver resume rqrd";
CM_ SG_ 1081 APP_w195_scwUnavailable "Driver assistance computer (primary): w195 scw unavailable";
CM_ SG_ 1081 APP_w196_stopSignWarning "Driver assistance computer (primary): w196 stop sign warning";
CM_ SG_ 1081 APP_w197_redLightWarning "Driver assistance computer (primary): w197 red light warning";
CM_ SG_ 1081 APP_w198_tsrUnavailable "Driver assistance computer (primary): w198 tsr unavailable";
CM_ SG_ 1081 APP_w199_apcAbort "Driver assistance computer (primary): w199 apc abort";
CM_ SG_ 1081 APP_w200_lcSlowdown "Driver assistance computer (primary): w200 lc slowdown";
CM_ SG_ 1081 APP_w201_lcAborting "Driver assistance computer (primary): w201 lc aborting";
CM_ SG_ 1081 APP_w202_scwNoisyEnvironment "Driver assistance computer (primary): w202 scw noisy environment";
CM_ SG_ 1081 APP_w203_apcActivation "Driver assistance computer (primary): w203 apc activation";
CM_ SG_ 1081 APP_w204_apcFinalFront "Driver assistance computer (primary): w204 apc final front";
CM_ SG_ 1081 APP_w205_apcFinalRear "Driver assistance computer (primary): w205 apc final rear";
CM_ SG_ 1081 APP_w206_autosteerNotEnabled "Driver assistance computer (primary): w206 autosteer not enabled";
CM_ SG_ 1081 APP_w207_autosteerUnavailable "Driver assistance computer (primary): w207 autosteer unavailable";
CM_ SG_ 1081 APP_w208_rackDetected "Driver assistance computer (primary): w208 rack detected";
CM_ SG_ 1081 APP_w209_autoSummonRequest "Driver assistance computer (primary): w209 auto summon request";
CM_ SG_ 1081 APP_w210_camObstrcted "Driver assistance computer (primary): w210 cam obstrcted";
CM_ SG_ 1081 APP_w211_accNoSeatBelt "Driver assistance computer (primary): w211 acc no seat belt";
CM_ SG_ 1081 APP_w212_lcUnavailableStrikeOut "Driver assistance computer (primary): w212 lc unavailable strike out";
CM_ SG_ 1081 APP_w213_autosteerStruckOut "Driver assistance computer (primary): w213 autosteer struck out";
CM_ SG_ 1081 APP_w214_driverNotIntracting "Driver assistance computer (primary): w214 driver not intracting";
CM_ SG_ 1081 APP_w215_contDriverNotIntracting "Driver assistance computer (primary): w215 cont driver not intracting";
CM_ SG_ 1081 APP_w216_driverOverriding "Driver assistance computer (primary): w216 driver overriding";
CM_ SG_ 1081 APP_w217_lcUnavailableSpeeding "Driver assistance computer (primary): w217 lc unavailable speeding";
CM_ SG_ 1081 APP_w218_lcSpeedExceededLimit "Driver assistance computer (primary): w218 lc speed exceeded limit";
CM_ SG_ 1081 APP_w219_lcTempUnavailableSpeed "Driver assistance computer (primary): w219 lc temp unavailable speed";
CM_ SG_ 1081 APP_w220_lcTempUnavailableRoad "Driver assistance computer (primary): w220 lc temp unavailable road";
CM_ SG_ 1081 APP_w221_accRadarBlind "Driver assistance computer (primary): w221 acc radar blind";
CM_ SG_ 1081 APP_w222_accCameraBlind "Driver assistance computer (primary): w222 acc camera blind";
CM_ SG_ 1081 APP_w223_accObjectInPath "Driver assistance computer (primary): w223 acc object in path";
CM_ SG_ 1081 APP_w224_accCameraCalibration "Driver assistance computer (primary): w224 acc camera calibration";
CM_ SG_ 1081 APP_w225_lcDegradedVisSpeedLmt "Driver assistance computer (primary): w225 lc degraded vis speed lmt";
CM_ SG_ 1081 APP_w226_lcCamCalNeededSpeedLmt "Driver assistance computer (primary): w226 lc cam cal needed speed lmt";
CM_ SG_ 1081 APP_w227_virtualWallBlocked "Driver assistance computer (primary): w227 virtual wall blocked";
CM_ SG_ 1081 APP_w228_DEPRECATED "Driver assistance computer (primary): w228 DEPRECATED";
CM_ SG_ 1081 APP_w229_alcUltrasoundDamaged "Driver assistance computer (primary): w229 alc ultrasound damaged";
CM_ SG_ 1081 APP_w230_alcUltrasoundBlocked "Driver assistance computer (primary): w230 alc ultrasound blocked";
CM_ SG_ 1081 APP_w231_idfEvent "Driver assistance computer (primary): w231 idf event";
CM_ SG_ 1081 APP_w232_laneChangeRequested "Driver assistance computer (primary): w232 lane change requested";
CM_ SG_ 1081 APP_w233_fsdQuizRequired "Driver assistance computer (primary): w233 fsd quiz required";
CM_ SG_ 1081 APP_w234_activeSafetyTelemetry "Driver assistance computer (primary): w234 active safety telemetry";
CM_ SG_ 1081 APP_w235_fsdRegionNotAllowed "Driver assistance computer (primary): w235 fsd region not allowed";
CM_ BO_ 1097 "Driver assistance computer (primary) message: warning matrix4";
CM_ SG_ 1097 APP_w257_brakeJerkEvent "Driver assistance computer (primary): w257 brake jerk event";
CM_ SG_ 1097 APP_w258_aebEvent "Driver assistance computer (primary): w258 aeb event";
CM_ SG_ 1097 APP_w259_aebOverrideEvent "Driver assistance computer (primary): w259 aeb override event";
CM_ SG_ 1097 APP_w260_collisionWarningEvent "Driver assistance computer (primary): w260 collision warning event";
CM_ SG_ 1097 APP_w261_pcieHardwareErrors "Driver assistance computer (primary): w261 pcie hardware errors";
CM_ SG_ 1097 APP_w262_apeCalibMode "Driver assistance computer (primary): w262 ape calib mode";
CM_ SG_ 1097 APP_w263_lssAbort "Driver assistance computer (primary): w263 lss abort";
CM_ SG_ 1097 APP_w264_lssFault "Driver assistance computer (primary): w264 lss fault";
CM_ SG_ 1097 APP_w265_drvOnNavUnavailable "Driver assistance computer (primary): w265 drv on nav unavailable";
CM_ SG_ 1097 APP_w266_visionScheduleFallback "Driver assistance computer (primary): w266 vision schedule fallback";
CM_ SG_ 1097 APP_w267_benchtopEcu "Driver assistance computer (primary): w267 benchtop ecu";
CM_ SG_ 1097 APP_w268_backupCamExtNotCal "Driver assistance computer (primary): w268 backup cam ext not cal";
CM_ SG_ 1097 APP_w269_autopilotLimited "Driver assistance computer (primary): w269 autopilot limited";
CM_ SG_ 1097 APP_w270_blindspotRestricted "Driver assistance computer (primary): w270 blindspot restricted";
CM_ SG_ 1097 APP_w271_laneChangeAborted "Driver assistance computer (primary): w271 lane change aborted";
CM_ SG_ 1097 APP_w272_laneChangeUnavailable "Driver assistance computer (primary): w272 lane change unavailable";
CM_ SG_ 1097 APP_w273_lssEvent "Driver assistance computer (primary): w273 lss event";
CM_ SG_ 1097 APP_w274_mainCameraStreamErr "Driver assistance computer (primary): w274 main camera stream err";
CM_ SG_ 1097 APP_w275_narrowCameraStreamErr "Driver assistance computer (primary): w275 narrow camera stream err";
CM_ SG_ 1097 APP_w276_fisheyeCameraStreamErr "Driver assistance computer (primary): w276 fisheye camera stream err";
CM_ SG_ 1097 APP_w277_lPillarCameraStreamErr "Driver assistance computer (primary): w277 l pillar camera stream err";
CM_ SG_ 1097 APP_w278_rPillarCameraStreamErr "Driver assistance computer (primary): w278 r pillar camera stream err";
CM_ SG_ 1097 APP_w279_lRepeatCameraStreamErr "Driver assistance computer (primary): w279 l repeat camera stream err";
CM_ SG_ 1097 APP_w280_rRepeatCameraStreamErr "Driver assistance computer (primary): w280 r repeat camera stream err";
CM_ SG_ 1097 APP_w281_backupCameraStreamErr "Driver assistance computer (primary): w281 backup camera stream err";
CM_ SG_ 1097 APP_w282_selfieCameraStreamErr "Driver assistance computer (primary): w282 selfie camera stream err";
CM_ SG_ 1097 APP_w283_enhancedSummonAbort "Driver assistance computer (primary): w283 enhanced summon abort";
CM_ SG_ 1097 APP_w284_gpsAntennaDisconnected "Driver assistance computer (primary): w284 gps antenna disconnected";
CM_ SG_ 1097 APP_w285_gpsFaultReset "Driver assistance computer (primary): w285 gps fault reset";
CM_ SG_ 1097 APP_w286_gpsComIssue "Driver assistance computer (primary): w286 gps com issue";
CM_ SG_ 1097 APP_w287_gpsFusionStatus "Driver assistance computer (primary): w287 gps fusion status";
CM_ SG_ 1097 APP_w288_trafficLightWarning "Driver assistance computer (primary): w288 traffic light warning";
CM_ SG_ 1097 APP_w289_dramCorrEccErrors "Driver assistance computer (primary): w289 dram corr ecc errors";
CM_ SG_ 1097 APP_w290_dramUncorrEccErrors "Driver assistance computer (primary): w290 dram uncorr ecc errors";
CM_ SG_ 1097 APP_w291_stopSignWarning "Driver assistance computer (primary): w291 stop sign warning";
CM_ SG_ 1097 APP_w293_mainCameraSyncFailed "Driver assistance computer (primary): w293 main camera sync failed";
CM_ SG_ 1097 APP_w294_narrowCameraSyncFailed "Driver assistance computer (primary): w294 narrow camera sync failed";
CM_ SG_ 1097 APP_w295_fisheyeCameraSyncFailed "Driver assistance computer (primary): w295 fisheye camera sync failed";
CM_ SG_ 1097 APP_w296_lPillarCameraSyncFailed "Driver assistance computer (primary): w296 l pillar camera sync failed";
CM_ SG_ 1097 APP_w297_rPillarCameraSyncFailed "Driver assistance computer (primary): w297 r pillar camera sync failed";
CM_ SG_ 1097 APP_w298_lRepeatCameraSyncFailed "Driver assistance computer (primary): w298 l repeat camera sync failed";
CM_ SG_ 1097 APP_w299_rRepeatCameraSyncFailed "Driver assistance computer (primary): w299 r repeat camera sync failed";
CM_ SG_ 1097 APP_w300_backupCameraSyncFailed "Driver assistance computer (primary): w300 backup camera sync failed";
CM_ SG_ 1097 APP_w301_selfieCameraSyncFailed "Driver assistance computer (primary): w301 selfie camera sync failed";
CM_ SG_ 1097 APP_w302_vcfrontMiaPartyBus "Driver assistance computer (primary): w302 vcfront mia party bus";
CM_ SG_ 1097 APP_w303_imuIrational "Driver assistance computer (primary): w303 imu irational";
CM_ SG_ 1097 APP_w304_lssCamBlockedStatus "Driver assistance computer (primary): w304 lss cam blocked status";
CM_ SG_ 1097 APP_w305_lssCamStreamExit "Driver assistance computer (primary): w305 lss cam stream exit";
CM_ SG_ 1097 APP_w306_lssUltrasonicsBlocked "Driver assistance computer (primary): w306 lss ultrasonics blocked";
CM_ SG_ 1097 APP_w307_lssTurnSignalFault "Driver assistance computer (primary): w307 lss turn signal fault";
CM_ SG_ 1097 APP_w308_iboosterMia "Driver assistance computer (primary): w308 ibooster mia";
CM_ SG_ 1097 APP_w309_selfieDisabledOnCar "Driver assistance computer (primary): w309 selfie disabled on car";
CM_ SG_ 1097 APP_w310_eth0FrameErrors "Driver assistance computer (primary): w310 eth0 frame errors";
CM_ SG_ 1097 APP_w311_eth1FrameErrors "Driver assistance computer (primary): w311 eth1 frame errors";
CM_ SG_ 1097 APP_w312_mainCamTypeMismatch "Driver assistance computer (primary): w312 main cam type mismatch";
CM_ SG_ 1097 APP_w313_narrowCamTypeMismatch "Driver assistance computer (primary): w313 narrow cam type mismatch";
CM_ SG_ 1097 APP_w314_fisheyeCamTypeMismatch "Driver assistance computer (primary): w314 fisheye cam type mismatch";
CM_ SG_ 1097 APP_w315_lPillarCamTypeMismatch "Driver assistance computer (primary): w315 l pillar cam type mismatch";
CM_ SG_ 1097 APP_w316_rPillarCamTypeMismatch "Driver assistance computer (primary): w316 r pillar cam type mismatch";
CM_ SG_ 1097 APP_w317_lRepeatCamTypeMismatch "Driver assistance computer (primary): w317 l repeat cam type mismatch";
CM_ SG_ 1097 APP_w318_rRepeatCamTypeMismatch "Driver assistance computer (primary): w318 r repeat cam type mismatch";
CM_ SG_ 1097 APP_w319_backupCamTypeMismatch "Driver assistance computer (primary): w319 backup cam type mismatch";
CM_ SG_ 1097 APP_w320_selfieCamTypeMismatch "Driver assistance computer (primary): w320 selfie cam type mismatch";
CM_ BO_ 1151 "Driver assistance computer (primary) message: warning matrix5";
CM_ SG_ 1151 APP_w321_bmsMia "Driver assistance computer (primary): w321 bms mia";
CM_ SG_ 1151 APP_w322_autoWiperWash "Driver assistance computer (primary): w322 auto wiper wash";
CM_ SG_ 1151 APP_w323_drivableSpaceFCW "Driver assistance computer (primary): w323 drivable space FCW";
CM_ SG_ 1151 APP_w324_adspMia "Driver assistance computer (primary): w324 adsp mia";
CM_ SG_ 1151 APP_w325_watchdogReset "Driver assistance computer (primary): w325 watchdog reset";
CM_ SG_ 1151 APP_w326_kernelPanic "Driver assistance computer (primary): w326 kernel panic";
CM_ SG_ 1151 APP_w327_vehicleConfigMismatch "Driver assistance computer (primary): w327 vehicle config mismatch";
CM_ SG_ 1151 APP_w328_autoparkDegraded "Driver assistance computer (primary): w328 autopark degraded";
CM_ SG_ 1151 APP_w329_evasiveManeuver "Driver assistance computer (primary): w329 evasive maneuver";
CM_ SG_ 1151 APP_w330_cabinCameraFault "Driver assistance computer (primary): w330 cabin camera fault";
CM_ SG_ 1151 APP_w331_fsdDegradedUnavailable "Driver assistance computer (primary): w331 fsd degraded unavailable";
CM_ SG_ 1151 APP_w332_cameraPositionsSwapped "Driver assistance computer (primary): w332 camera positions swapped";
CM_ SG_ 1151 APP_w333_fsdUnavailableLocation "Driver assistance computer (primary): w333 fsd unavailable location";
CM_ SG_ 1151 APP_w334_frontCameraOccluded "Driver assistance computer (primary): w334 front camera occluded";
CM_ SG_ 1151 APP_w335_tradfcRfSensorError "Driver assistance computer (primary): w335 tradfc rf sensor error";
CM_ SG_ 1151 APP_w336_tradfcLfPmicError "Driver assistance computer (primary): w336 tradfc lf pmic error";
CM_ SG_ 1151 APP_w337_tradfcRfPmicError "Driver assistance computer (primary): w337 tradfc rf pmic error";
CM_ SG_ 1151 APP_w338_tradfcLfTempError "Driver assistance computer (primary): w338 tradfc lf temp error";
CM_ SG_ 1151 APP_w339_tradfcRfTempError "Driver assistance computer (primary): w339 tradfc rf temp error";
CM_ SG_ 1151 APP_w340_tradfcCsiError "Driver assistance computer (primary): w340 tradfc csi error";
CM_ SG_ 1151 APP_w341_tradfcCalibError "Driver assistance computer (primary): w341 tradfc calib error";
CM_ SG_ 1151 APP_w342_tradfcDspHwError "Driver assistance computer (primary): w342 tradfc dsp hw error";
CM_ SG_ 1151 APP_w343_tradfcDspSwError "Driver assistance computer (primary): w343 tradfc dsp sw error";
CM_ SG_ 1151 APP_w344_tradfcDspAlgoTimeout "Driver assistance computer (primary): w344 tradfc dsp algo timeout";
CM_ SG_ 1151 APP_w345_tradfcPerfDegraded "Driver assistance computer (primary): w345 tradfc perf degraded";
CM_ SG_ 1151 APP_w346_gpsSwEvent "Driver assistance computer (primary): w346 gps sw event";
CM_ SG_ 1151 APP_w347_vcbattMiaVehBus "Driver assistance computer (primary): w347 vcbatt mia veh bus";
CM_ SG_ 1151 APP_w348_cameraSwUpdateRequired "Driver assistance computer (primary): w348 camera sw update required";
CM_ SG_ 1151 APP_w349_cameraPersistentlyFault "Driver assistance computer (primary): w349 camera persistently faulted";
CM_ SG_ 1151 APP_w350_tradfcSensorMisaligned "Driver assistance computer (primary): w350 tradfc sensor misaligned";
CM_ SG_ 1151 APP_w351_csiDevice0Down "Driver assistance computer (primary): w351 csi device0 down";
CM_ SG_ 1151 APP_w352_csiDevice1Down "Driver assistance computer (primary): w352 csi device1 down";
CM_ SG_ 1151 APP_w353_csiDevice2Down "Driver assistance computer (primary): w353 csi device2 down";
CM_ SG_ 1151 APP_w354_tradfcMia "Driver assistance computer (primary): w354 tradfc mia";
CM_ SG_ 1151 APP_w355_camQuadPowerFault "Driver assistance computer (primary): w355 cam quad power fault";
CM_ SG_ 1151 APP_w356_driverOverriding "Driver assistance computer (primary): w356 driver overriding";
CM_ SG_ 1151 APP_w357_ddawSystemFault "Driver assistance computer (primary): w357 ddaw system fault";
CM_ SG_ 1151 APP_w358_isaSystemFault "Driver assistance computer (primary): w358 isa system fault";
CM_ SG_ 1151 APP_w359_aebDegraded "Driver assistance computer (primary): w359 aeb degraded";
CM_ SG_ 1151 APP_w360_apImuNoiseDetected "Driver assistance computer (primary): w360 ap imu noise detected";
CM_ SG_ 1151 APP_w361_cabinCameraLEDFault "Driver assistance computer (primary): w361 cabin camera LED fault";
CM_ SG_ 1151 APP_w362_fasciaCamInitFault "Driver assistance computer (primary): w362 fascia cam init fault";
CM_ SG_ 1151 APP_w363_fasciaCameraStreamExit "Driver assistance computer (primary): w363 fascia camera stream exit";
CM_ SG_ 1151 APP_w364_fasciaCameraTypeError "Driver assistance computer (primary): w364 fascia camera type error";
CM_ SG_ 1151 APP_w365_fasciaCamExtNotCal "Driver assistance computer (primary): w365 fascia cam ext not cal";
CM_ SG_ 1151 APP_w366_fasciaCameraSyncFailed "Driver assistance computer (primary): w366 fascia camera sync failed";
CM_ SG_ 1151 APP_w367_fasciaCamCalSaved "Driver assistance computer (primary): w367 fascia cam cal saved";
CM_ SG_ 1151 APP_w368_fasciaCamTypeMismatch "Driver assistance computer (primary): w368 fascia cam type mismatch";
CM_ SG_ 1151 APP_w369_cruiseWithSingleClick "Driver assistance computer (primary): w369 cruise with single click";
CM_ SG_ 1151 APP_w370_accApUnavUserSettings "Driver assistance computer (primary): w370 acc ap unav user settings";
CM_ SG_ 1151 APP_w371_networkLoadingIssue "Driver assistance computer (primary): w371 network loading issue";
CM_ SG_ 1151 APP_w372_cabinCameraBlocked "Driver assistance computer (primary): w372 cabin camera blocked";
CM_ SG_ 1151 APP_w373_gnssUartError "Driver assistance computer (primary): w373 gnss uart error";
CM_ SG_ 1151 APP_w374_gnssDataMia "Driver assistance computer (primary): w374 gnss data mia";
CM_ SG_ 1151 APP_w375_gnssPpsMia "Driver assistance computer (primary): w375 gnss pps mia";
CM_ SG_ 1151 APP_w376_wheeltickCountMia "Driver assistance computer (primary): w376 wheeltick count mia";
CM_ SG_ 1151 APP_w377_apImuMia "Driver assistance computer (primary): w377 ap imu mia";
CM_ SG_ 1151 APP_w378_ubloxImuMia "Driver assistance computer (primary): w378 ublox imu mia";
CM_ SG_ 1151 APP_w379_positioningEngineMia "Driver assistance computer (primary): w379 positioning engine mia";
CM_ SG_ 1151 APP_w380_gnssPpsTimestampIssue "Driver assistance computer (primary): w380 gnss pps timestamp issue";
CM_ SG_ 1151 APP_w381_apImuTimestampIssue "Driver assistance computer (primary): w381 ap imu timestamp issue";
CM_ SG_ 1151 APP_w382_ubloxImuTimestampIssue "Driver assistance computer (primary): w382 ublox imu timestamp issue";
CM_ SG_ 1151 APP_w383_manyApRebootsWhileInP "Driver assistance computer (primary): w383 many ap reboots while in p";
CM_ SG_ 1151 APP_w384_posEngineInitInMotion "Driver assistance computer (primary): w384 pos engine init in motion";
CM_ BO_ 1149 "Driver assistance computer (primary) message: warning matrix6";
CM_ SG_ 1149 APP_w385_posEngineUnhealthy "Driver assistance computer (primary): w385 pos engine unhealthy";
CM_ SG_ 1149 APP_w386_radarOnlyBrakingEvent "Driver assistance computer (primary): w386 radar only braking event";
CM_ SG_ 1149 APP_w387_radarBlockageDetected "Driver assistance computer (primary): w387 radar blockage detected";
CM_ SG_ 1149 APP_w388_windshieldCameraHeaterF "Driver assistance computer (primary): w388 windshield camera heater faulted";
CM_ SG_ 1149 APP_w389_camFovResidueDetected "Driver assistance computer (primary): w389 cam fov residue detected";
CM_ SG_ 1149 APP_w390_cabinCamVisDegraded "Driver assistance computer (primary): w390 cabin cam vis degraded";
CM_ SG_ 1149 APP_w391_cabinCameraBlockedonAP "Driver assistance computer (primary): w391 cabin camera blockedon AP";
CM_ SG_ 1149 APP_w392_fsdSuspended "Driver assistance computer (primary): w392 fsd suspended";
CM_ SG_ 1149 APP_w393_attnMntrUnavailable "Driver assistance computer (primary): w393 attn mntr unavailable";
CM_ SG_ 1149 APP_w394_apImuGrossErrors "Driver assistance computer (primary): w394 ap imu gross errors";
CM_ SG_ 1149 APP_w395_cabinCameraLEDFaultSvc "Driver assistance computer (primary): w395 cabin camera LED fault svc";
CM_ SG_ 1149 APP_w396_severeResidueDetected "Driver assistance computer (primary): w396 severe residue detected";
CM_ SG_ 1149 APP_w397_apFeatDisabledPermanent "Driver assistance computer (primary): w397 ap feat disabled permanent";
CM_ SG_ 1149 APP_w398_imuOutputUnhealthy "Driver assistance computer (primary): w398 imu output unhealthy";
CM_ SG_ 1149 APP_w399_brakeboosterMia "Driver assistance computer (primary): w399 brakebooster mia";
CM_ SG_ 1149 APP_w400_selfieCameraFanFault "Driver assistance computer (primary): w400 selfie camera fan fault";
CM_ SG_ 1149 APP_w401_leftPillarCameraHeaterF "Driver assistance computer (primary): w401 left pillar camera heater faulted";
CM_ SG_ 1149 APP_w402_rightPillarCameraHeater "Driver assistance computer (primary): w402 right pillar camera heater faulted";
CM_ SG_ 1149 APP_w403_notifyCameraSelfCleanAc "Driver assistance computer (primary): w403 notify camera self clean action";
CM_ SG_ 1149 APP_w404_epbrMiaVehBus "Driver assistance computer (primary): w404 epbr mia veh bus";
CM_ SG_ 1149 APP_w405_apsMia "Driver assistance computer (primary): w405 aps mia";
CM_ SG_ 1149 APP_w406_gnssHWHealthDegraded "Driver assistance computer (primary): w406 gnss HW health degraded";
CM_ SG_ 1149 APP_w407_autonomyDegraded1 "Driver assistance computer (primary): w407 autonomy degraded1";
CM_ SG_ 1149 APP_w408_autonomyDegraded2 "Driver assistance computer (primary): w408 autonomy degraded2";
CM_ SG_ 1149 APP_w409_autonomyDegraded3 "Driver assistance computer (primary): w409 autonomy degraded3";
CM_ SG_ 1149 APP_w410_autonomyDegraded4 "Driver assistance computer (primary): w410 autonomy degraded4";
CM_ SG_ 1149 APP_w411_backupCameraOccluded "Driver assistance computer (primary): w411 backup camera occluded";
CM_ SG_ 1149 APP_w412_abortBackupCamOccluded "Driver assistance computer (primary): w412 abort backup cam occluded";
CM_ SG_ 1149 APP_w413_autonomyDegraded5 "Driver assistance computer (primary): w413 autonomy degraded5";
CM_ SG_ 1149 APP_w415_autonomyUnavailableSyst "Driver assistance computer (primary): w415 autonomy unavailable system";
CM_ SG_ 1149 APP_w416_autonomyDegradedSystem "Driver assistance computer (primary): w416 autonomy degraded system";
CM_ SG_ 1149 APP_w417_autonomyUnavailableVisi "Driver assistance computer (primary): w417 autonomy unavailable visibility";
CM_ SG_ 1149 APP_w418_autonomyDegradedVisibil "Driver assistance computer (primary): w418 autonomy degraded visibility";
CM_ SG_ 1149 APP_w419_autonomyUnavailableApSy "Driver assistance computer (primary): w419 autonomy unavailable ap system";
CM_ SG_ 1149 APP_w420_autonomyDegradedApSyste "Driver assistance computer (primary): w420 autonomy degraded ap system";
CM_ SG_ 1149 APP_w421_autonomyUnavailableUser "Driver assistance computer (primary): w421 autonomy unavailable user";
CM_ SG_ 1149 APP_w422_autonomyDegradedUser "Driver assistance computer (primary): w422 autonomy degraded user";
CM_ SG_ 1149 APP_w423_cameraVisPopUpForward "Driver assistance computer (primary): w423 camera vis pop up forward";
CM_ SG_ 1149 APP_w424_cameraVisPopUpLPillar "Driver assistance computer (primary): w424 camera vis pop up l pillar";
CM_ SG_ 1149 APP_w425_cameraVisPopUpRPillar "Driver assistance computer (primary): w425 camera vis pop up r pillar";
CM_ SG_ 1149 APP_w426_cameraVisPopUpLRepeater "Driver assistance computer (primary): w426 camera vis pop up l repeater";
CM_ SG_ 1149 APP_w427_cameraVisPopUpRRepeater "Driver assistance computer (primary): w427 camera vis pop up r repeater";
CM_ SG_ 1149 APP_w428_cameraVisPopUpBackup "Driver assistance computer (primary): w428 camera vis pop up backup";
CM_ SG_ 1149 APP_w429_cameraVisPopUpFascia "Driver assistance computer (primary): w429 camera vis pop up fascia";
CM_ SG_ 1149 APP_w430_frontVisibilityDegraded "Driver assistance computer (primary): w430 front visibility degraded LOW";
CM_ SG_ 1149 APP_w431_frontVisibilityDegraded "Driver assistance computer (primary): w431 front visibility degraded MEDIUM";
CM_ SG_ 1149 APP_w432_frontVisibilityDegraded "Driver assistance computer (primary): w432 front visibility degraded HIGH";
CM_ SG_ 1149 APP_w433_leftRepeaterDowngradeDe "Driver assistance computer (primary): w433 left repeater downgrade detected";
CM_ SG_ 1149 APP_w434_rightRepeaterDowngradeD "Driver assistance computer (primary): w434 right repeater downgrade detected";
CM_ SG_ 1149 APP_w435_repeaterAeroRibInfoMism "Driver assistance computer (primary): w435 repeater aero rib info mismatched";
CM_ SG_ 1149 APP_w436_camCsiError "Driver assistance computer (primary): w436 cam csi error";
CM_ SG_ 1149 APP_w437_missingCloudEepromData "Driver assistance computer (primary): w437 missing cloud eeprom data";
CM_ SG_ 1149 APP_w438_rcuMia "Driver assistance computer (primary): w438 rcu mia";
CM_ SG_ 1149 APP_w439_ethernetCommFailure "Driver assistance computer (primary): w439 ethernet comm failure";
CM_ SG_ 1149 APP_w440_lensHoodOcclusion "Driver assistance computer (primary): w440 lens hood occlusion";
CM_ SG_ 1149 APP_w441_cabinCamLEDRailOff "Driver assistance computer (primary): w441 cabin cam LED rail off";
CM_ SG_ 1149 APP_w442_autonomyCancelMethod "Driver assistance computer (primary): w442 autonomy cancel method";
CM_ SG_ 1149 APP_w443_mainImagerConfigMismatc "Driver assistance computer (primary): w443 main imager config mismatch";
CM_ SG_ 1149 APP_w444_narrowImagerConfigMisma "Driver assistance computer (primary): w444 narrow imager config mismatch";
CM_ SG_ 1149 APP_w445_fisheyeImagerConfigMism "Driver assistance computer (primary): w445 fisheye imager config mismatch";
CM_ SG_ 1149 APP_w446_leftPillarImagerConfigM "Driver assistance computer (primary): w446 left pillar imager config mismatch";
CM_ SG_ 1149 APP_w447_rightPillarImagerConfig "Driver assistance computer (primary): w447 right pillar imager config mismatch";
CM_ SG_ 1149 APP_w448_leftRepeaterImagerConfi "Driver assistance computer (primary): w448 left repeater imager config mismatch";
CM_ BO_ 1233 "Driver assistance computer (primary) message: warning matrix7";
CM_ SG_ 1233 APP_w449_rightRepeaterImagerConf "Driver assistance computer (primary): w449 right repeater imager config mismatch";
CM_ SG_ 1233 APP_w450_backupImagerConfigMisma "Driver assistance computer (primary): w450 backup imager config mismatch";
CM_ SG_ 1233 APP_w451_fasciaImagerConfigMisma "Driver assistance computer (primary): w451 fascia imager config mismatch";
CM_ SG_ 1233 APP_w452_selfieImagerConfigMisma "Driver assistance computer (primary): w452 selfie imager config mismatch";
CM_ SG_ 1233 APP_w453_driverCancelBlinker "Driver assistance computer (primary): w453 driver cancel blinker";
CM_ SG_ 1233 APP_w454_appAutonomySystemUnheal "Driver assistance computer (primary): w454 app autonomy system unhealthy";
CM_ SG_ 1233 APP_w455_apbAutonomySystemUnheal "Driver assistance computer (primary): w455 apb autonomy system unhealthy";
CM_ SG_ 1233 APP_w456_autonomyUnavailableColl "Driver assistance computer (primary): w456 autonomy unavailable collision";
CM_ SG_ 1233 APP_w457_autonomyDegradedCollisi "Driver assistance computer (primary): w457 autonomy degraded collision";
CM_ SG_ 1233 APP_w458_aceEvent "Driver assistance computer (primary): w458 ace event";
CM_ SG_ 1233 APP_w459_epbrMiaPartyBus "Driver assistance computer (primary): w459 epbr mia party bus";
CM_ SG_ 1233 APP_w460_epblMiaChBus "Driver assistance computer (primary): w460 epbl mia ch bus";
CM_ SG_ 1233 APP_w461_autonomyReroute "Driver assistance computer (primary): w461 autonomy reroute";
CM_ SG_ 1233 APP_w462_selfDrivingUnavailable "Driver assistance computer (primary): w462 self driving unavailable";
CM_ SG_ 1233 APP_w463_selfDrivingCamObstrcted "Driver assistance computer (primary): w463 self driving cam obstrcted";
CM_ SG_ 1233 APP_w464_autonomyUnavailableODD "Driver assistance computer (primary): w464 autonomy unavailable ODD";
CM_ SG_ 1233 APP_w465_autonomyDegradedODD "Driver assistance computer (primary): w465 autonomy degraded ODD";
CM_ SG_ 1233 APP_w466_missingSensorOTP "Driver assistance computer (primary): w466 missing sensor OTP";
CM_ SG_ 1233 APP_w467_imuDegraded "Driver assistance computer (primary): w467 imu degraded";
CM_ SG_ 1233 APP_w477_driverSeatReclined "Driver assistance computer (primary): w477 driver seat reclined";
CM_ SG_ 1233 APP_w478_runModeSwitch "Driver assistance computer (primary): w478 run mode switch";
CM_ SG_ 1233 APP_w482_appVisionFailoverActiva "Driver assistance computer (primary): w482 app vision failover activated";
CM_ SG_ 1233 APP_w483_apbVisionFailoverActiva "Driver assistance computer (primary): w483 apb vision failover activated";
BA_DEF_ BO_ "GenMsgCycleTime" INT 0 3600000;
BA_DEF_ BO_ "GenMsgSendType" ENUM "Cyclic","NotUsed","NotUsed","NotUsed","NotUsed","NotUsed","NotUsed","IfActive","NoMsgSendType","NotUsed";
BA_DEF_ BO_ "VFrameFormat" ENUM "StandardCAN","ExtendedCAN","reserved","J1939PG","reserved","reserved","reserved","reserved","reserved","reserved","reserved","reserved","reserved","reserved","StandardCAN_FD","ExtendedCAN_FD";
BA_DEF_ BO_ "CANFD_BRS" ENUM "0","1";
BA_DEF_ SG_ "GenSigSNA" STRING;
BA_DEF_ SG_ "SystemSignalLongSymbol" STRING;
BA_DEF_ SG_ "Confidence" ENUM "validated","plausible","layout-only","contradicted";
BA_DEF_DEF_ "GenMsgCycleTime" 0;
BA_DEF_DEF_ "GenMsgSendType" "NoMsgSendType";
BA_DEF_DEF_ "VFrameFormat" "StandardCAN";
BA_DEF_DEF_ "CANFD_BRS" "1";
BA_DEF_DEF_ "GenSigSNA" "";
BA_DEF_DEF_ "SystemSignalLongSymbol" "";
BA_DEF_DEF_ "Confidence" "layout-only";
BA_ "GenMsgCycleTime" BO_ 601 100;
BA_ "GenMsgSendType" BO_ 601 0;
BA_ "GenMsgCycleTime" BO_ 605 500;
BA_ "GenMsgSendType" BO_ 605 0;
BA_ "GenMsgCycleTime" BO_ 859 100;
BA_ "GenMsgSendType" BO_ 859 0;
BA_ "GenMsgCycleTime" BO_ 809 1000;
BA_ "GenMsgSendType" BO_ 809 0;
BA_ "GenMsgCycleTime" BO_ 873 1000;
BA_ "GenMsgSendType" BO_ 873 0;
BA_ "GenMsgCycleTime" BO_ 1065 1000;
BA_ "GenMsgSendType" BO_ 1065 0;
BA_ "GenMsgCycleTime" BO_ 1081 1000;
BA_ "GenMsgSendType" BO_ 1081 0;
BA_ "GenMsgCycleTime" BO_ 1097 1000;
BA_ "GenMsgSendType" BO_ 1097 0;
BA_ "GenMsgCycleTime" BO_ 1151 1000;
BA_ "GenMsgSendType" BO_ 1151 0;
BA_ "GenMsgCycleTime" BO_ 1149 1000;
BA_ "GenMsgSendType" BO_ 1149 0;
BA_ "GenMsgCycleTime" BO_ 1233 1000;
BA_ "GenMsgSendType" BO_ 1233 0;
BA_ "Confidence" SG_ 601 APP_watchdogState 0;
BA_ "GenSigSNA" SG_ 601 APP_watchdogState "7";
BA_ "Confidence" SG_ 601 APP_fusedState 0;
BA_ "GenSigSNA" SG_ 601 APP_fusedState "3";
BA_ "Confidence" SG_ 601 APP_cameraHeaterRequest 0;
BA_ "Confidence" SG_ 601 APP_factorySummonStatus 0;
BA_ "GenSigSNA" SG_ 601 APP_factorySummonStatus "0";
BA_ "Confidence" SG_ 601 APP_clipRecordingStatus 0;
BA_ "Confidence" SG_ 601 APP_allowApActivationWithBrake 0;
BA_ "Confidence" SG_ 601 APP_summonUnavailableReason 0;
BA_ "Confidence" SG_ 601 APP_fsdSuspendState 0;
BA_ "GenSigSNA" SG_ 601 APP_fsdSuspendState "3";
BA_ "Confidence" SG_ 601 APP_fsdRevokeStrikeoutCount 0;
BA_ "GenSigSNA" SG_ 601 APP_fsdRevokeStrikeoutCount "7";
BA_ "Confidence" SG_ 601 APP_teslaVisionSupported 0;
BA_ "GenSigSNA" SG_ 601 APP_teslaVisionSupported "3";
BA_ "Confidence" SG_ 601 APP_teslaVisionUnsupportedReason 0;
BA_ "Confidence" SG_ 601 APP_fsdRevokeCount 0;
BA_ "GenSigSNA" SG_ 601 APP_fsdRevokeCount "7";
BA_ "Confidence" SG_ 601 APP_excessiveAccelPedalWarning 0;
BA_ "Confidence" SG_ 601 APP_unifiedObjectStackSupported 0;
BA_ "GenSigSNA" SG_ 601 APP_unifiedObjectStackSupported "3";
BA_ "Confidence" SG_ 601 APP_sendingBUCStream 0;
BA_ "Confidence" SG_ 601 APP_DDAWSystemStatus 0;
BA_ "GenSigSNA" SG_ 601 APP_DDAWSystemStatus "4";
BA_ "Confidence" SG_ 601 APP_socOperatingMode 0;
BA_ "Confidence" SG_ 601 APP_summonVersionIdentifier 0;
BA_ "Confidence" SG_ 601 APP_sentryState 0;
BA_ "GenSigSNA" SG_ 601 APP_sentryState "6";
BA_ "Confidence" SG_ 601 APP_autoparkVersionIdentifier 0;
BA_ "Confidence" SG_ 601 APP_autonomySystemHealth 0;
BA_ "Confidence" SG_ 601 APP_uiEthFailoverDisabled 0;
BA_ "Confidence" SG_ 601 APP_suspendResumeAvailable 0;
BA_ "Confidence" SG_ 601 APP_statusCounter 0;
BA_ "Confidence" SG_ 601 APP_statusChecksum 0;
BA_ "Confidence" SG_ 605 APP_tcFeatureState 0;
BA_ "Confidence" SG_ 605 APP_tcStateMachine 0;
BA_ "Confidence" SG_ 605 APP_tcControlSource 0;
BA_ "Confidence" SG_ 605 APP_tcControlType 0;
BA_ "Confidence" SG_ 605 APP_tcControlDistance 0;
BA_ "GenSigSNA" SG_ 605 APP_tcControlDistance "255";
BA_ "Confidence" SG_ 605 APP_tcControlLightState 0;
BA_ "Confidence" SG_ 605 APP_tcContinuationReason 0;
BA_ "Confidence" SG_ 605 APP_tcConfirmationType 0;
BA_ "Confidence" SG_ 605 APP_tcWarningSuppressionReason 0;
BA_ "Confidence" SG_ 605 APP_tcUnavailableReason 0;
BA_ "Confidence" SG_ 605 APP_tcVisionLight 0;
BA_ "Confidence" SG_ 605 APP_tcVisionSign 0;
BA_ "Confidence" SG_ 605 APP_tcVisionRoadMarking 0;
BA_ "Confidence" SG_ 605 APP_tcVisionLine 0;
BA_ "Confidence" SG_ 859 APP_visionOcsStatusChecksum 0;
BA_ "Confidence" SG_ 859 APP_visionOcsStateRaw 0;
BA_ "Confidence" SG_ 859 APP_visionOcsEmptyProbRaw 0;
BA_ "GenSigSNA" SG_ 859 APP_visionOcsEmptyProbRaw "255";
BA_ "Confidence" SG_ 859 APP_visionOcsChildProbRaw 0;
BA_ "GenSigSNA" SG_ 859 APP_visionOcsChildProbRaw "255";
BA_ "Confidence" SG_ 859 APP_visionOcsAdultProbRaw 0;
BA_ "GenSigSNA" SG_ 859 APP_visionOcsAdultProbRaw "255";
BA_ "Confidence" SG_ 859 APP_visionOcsFrontPasClsVisionSt 0;
BA_ "SystemSignalLongSymbol" SG_ 859 APP_visionOcsFrontPasClsVisionSt "APP_visionOcsFrontPasClsVisionStateFlt";
BA_ "Confidence" SG_ 859 APP_visionOcsStatusCounter 0;
BA_ "SystemSignalLongSymbol" SG_ 1151 APP_w349_cameraPersistentlyFault "APP_w349_cameraPersistentlyFaulted";
BA_ "SystemSignalLongSymbol" SG_ 1149 APP_w388_windshieldCameraHeaterF "APP_w388_windshieldCameraHeaterFaulted";
BA_ "SystemSignalLongSymbol" SG_ 1149 APP_w401_leftPillarCameraHeaterF "APP_w401_leftPillarCameraHeaterFaulted";
BA_ "SystemSignalLongSymbol" SG_ 1149 APP_w402_rightPillarCameraHeater "APP_w402_rightPillarCameraHeaterFaulted";
BA_ "SystemSignalLongSymbol" SG_ 1149 APP_w403_notifyCameraSelfCleanAc "APP_w403_notifyCameraSelfCleanAction";
BA_ "SystemSignalLongSymbol" SG_ 1149 APP_w415_autonomyUnavailableSyst "APP_w415_autonomyUnavailableSystem";
BA_ "SystemSignalLongSymbol" SG_ 1149 APP_w417_autonomyUnavailableVisi "APP_w417_autonomyUnavailableVisibility";
BA_ "SystemSignalLongSymbol" SG_ 1149 APP_w418_autonomyDegradedVisibil "APP_w418_autonomyDegradedVisibility";
BA_ "SystemSignalLongSymbol" SG_ 1149 APP_w419_autonomyUnavailableApSy "APP_w419_autonomyUnavailableApSystem";
BA_ "SystemSignalLongSymbol" SG_ 1149 APP_w420_autonomyDegradedApSyste "APP_w420_autonomyDegradedApSystem";
BA_ "SystemSignalLongSymbol" SG_ 1149 APP_w430_frontVisibilityDegraded "APP_w430_frontVisibilityDegraded_LOW";
BA_ "SystemSignalLongSymbol" SG_ 1149 APP_w431_frontVisibilityDegraded "APP_w431_frontVisibilityDegraded_MEDIUM";
BA_ "SystemSignalLongSymbol" SG_ 1149 APP_w432_frontVisibilityDegraded "APP_w432_frontVisibilityDegraded_HIGH";
BA_ "SystemSignalLongSymbol" SG_ 1149 APP_w433_leftRepeaterDowngradeDe "APP_w433_leftRepeaterDowngradeDetected";
BA_ "SystemSignalLongSymbol" SG_ 1149 APP_w434_rightRepeaterDowngradeD "APP_w434_rightRepeaterDowngradeDetected";
BA_ "SystemSignalLongSymbol" SG_ 1149 APP_w435_repeaterAeroRibInfoMism "APP_w435_repeaterAeroRibInfoMismatched";
BA_ "SystemSignalLongSymbol" SG_ 1149 APP_w443_mainImagerConfigMismatc "APP_w443_mainImagerConfigMismatch";
BA_ "SystemSignalLongSymbol" SG_ 1149 APP_w444_narrowImagerConfigMisma "APP_w444_narrowImagerConfigMismatch";
BA_ "SystemSignalLongSymbol" SG_ 1149 APP_w445_fisheyeImagerConfigMism "APP_w445_fisheyeImagerConfigMismatch";
BA_ "SystemSignalLongSymbol" SG_ 1149 APP_w446_leftPillarImagerConfigM "APP_w446_leftPillarImagerConfigMismatch";
BA_ "SystemSignalLongSymbol" SG_ 1149 APP_w447_rightPillarImagerConfig "APP_w447_rightPillarImagerConfigMismatch";
BA_ "SystemSignalLongSymbol" SG_ 1149 APP_w448_leftRepeaterImagerConfi "APP_w448_leftRepeaterImagerConfigMismatch";
BA_ "SystemSignalLongSymbol" SG_ 1233 APP_w449_rightRepeaterImagerConf "APP_w449_rightRepeaterImagerConfigMismatch";
BA_ "SystemSignalLongSymbol" SG_ 1233 APP_w450_backupImagerConfigMisma "APP_w450_backupImagerConfigMismatch";
BA_ "SystemSignalLongSymbol" SG_ 1233 APP_w451_fasciaImagerConfigMisma "APP_w451_fasciaImagerConfigMismatch";
BA_ "SystemSignalLongSymbol" SG_ 1233 APP_w452_selfieImagerConfigMisma "APP_w452_selfieImagerConfigMismatch";
BA_ "SystemSignalLongSymbol" SG_ 1233 APP_w454_appAutonomySystemUnheal "APP_w454_appAutonomySystemUnhealthy";
BA_ "SystemSignalLongSymbol" SG_ 1233 APP_w455_apbAutonomySystemUnheal "APP_w455_apbAutonomySystemUnhealthy";
BA_ "SystemSignalLongSymbol" SG_ 1233 APP_w456_autonomyUnavailableColl "APP_w456_autonomyUnavailableCollision";
BA_ "SystemSignalLongSymbol" SG_ 1233 APP_w457_autonomyDegradedCollisi "APP_w457_autonomyDegradedCollision";
BA_ "SystemSignalLongSymbol" SG_ 1233 APP_w482_appVisionFailoverActiva "APP_w482_appVisionFailoverActivated";
BA_ "SystemSignalLongSymbol" SG_ 1233 APP_w483_apbVisionFailoverActiva "APP_w483_apbVisionFailoverActivated";
VAL_ 601 APP_watchdogState 7 "AP_WDOG_STATE_SNA" 4 "AP_WDOG_STATE_SHUTTING_DOWN" 3 "AP_WDOG_STATE_HEALTHY" 2 "AP_WDOG_STATE_CRITICAL" 1 "AP_WDOG_STATE_DEGRADED" 0 "AP_WDOG_STATE_UNKNOWN" ;
VAL_ 601 APP_fusedState 3 "APP_FUSE_SNA" 2 "APP_FUSE_FUSED" 1 "APP_FUSE_UNFUSED" 0 "APP_FUSE_UNKNOWN" ;
VAL_ 601 APP_factorySummonStatus 8 "FACTORY_SUMMON_END_OF_ROUTE" 7 "FACTORY_SUMMON_UNAVAILABLE_HEADING_NOT_INITIALIZED" 6 "FACTORY_SUMMON_UNAVAILABLE_VEHICLE_SPEED_INVALID" 5 "FACTORY_SUMMON_UNAVAILABLE_NO_GPS" 4 "FACTORY_SUMMON_UNAVAILABLE_GOAL_TOO_FAR" 3 "FACTORY_SUMMON_UNAVAILABLE_NO_QR_INSTRUCTION" 2 "FACTORY_SUMMON_AVAILABLE" 1 "FACTORY_SUMMON_ACTIVE" 0 "FACTORY_SUMMON_SNA" ;
VAL_ 601 APP_clipRecordingStatus 4 "APP_CLIP_FAULTED" 3 "APP_CLIP_TRIGGERED" 2 "APP_CLIP_RECORDING" 1 "APP_CLIP_IDLE" 0 "APP_CLIP_NO_DRIVE" ;
VAL_ 601 APP_summonUnavailableReason 28 "SMART_SUMMON_UNAVAILABLE_OUTSIDE_GEOFENCE" 27 "SMART_SUMMON_UNAVAILABLE_ACCEL_PEDAL_PRESSED" 26 "SMART_SUMMON_UNAVAILABLE_BRAKE_PEDAL_PRESSED" 25 "SMART_SUMMON_UNAVAILABLE_REMOTE_STOP_OR_ABORT_REQUEST_ACTIVE" 24 "SMART_SUMMON_UNAVAILABLE_CLOSURE_OPEN" 23 "SMART_SUMMON_UNAVAILABLE_LOW_TIRE_PRESSURE" 22 "SMART_SUMMON_UNAVAILABLE_EXTENDED_COMPUTE_INACTIVE" 21 "SMART_SUMMON_UNAVAILABLE_HIGH_GRADE" 20 "SMART_SUMMON_UNAVAILABLE_NO_CONTEXT" 19 "SMART_SUMMON_UNAVAILABLE_PUBLIC_ROAD_BOUNDARIES_NOT_VALID" 18 "SMART_SUMMON_UNAVAILABLE_ALL_SENSORS_OCCLUDED" 17 "SMART_SUMMON_UNAVAILABLE_ULTRASONIC_STALE" 16 "SMART_SUMMON_UNAVAILABLE_VISION_HEALTH_CRITICAL" 15 "SMART_SUMMON_UNAVAILABLE_CAMERA_NOT_CALIBRATED" 14 "SMART_SUMMON_UNAVAILABLE_END_OF_LEASH" 13 "SMART_SUMMON_UNAVAILABLE_PHONE_IS_TOO_FAR" 12 "SMART_SUMMON_UNAVAILABLE_EGO_GPS_UNAVAILABLE" 11 "SMART_SUMMON_UNAVAILABLE_PHONE_GPS_UNAVAILABLE" 10 "SMART_SUMMON_UNAVAILABLE_POOR_CONNECTION" 9 "SMART_SUMMON_UNAVAILABLE_PUBLIC_ROAD" 8 "SMART_SUMMON_UNAVAILABLE_EAC_UNAVAILABLE" 7 "SMART_SUMMON_UNAVAILABLE_CRUISE_UNAVAILABLE" 6 "SMART_SUMMON_UNAVAILABLE_ULTRASONIC_FAULT" 5 "SMART_SUMMON_UNAVAILABLE_ULTRASONIC_BLOCKED" 4 "SMART_SUMMON_UNAVAILABLE_CAMERA_BLOCKED" 3 "SMART_SUMMON_UNAVAILABLE_CAMERA_STREAM" 2 "SMART_SUMMON_UNAVAILABLE_NOT_IN_PARK" 1 "SMART_SUMMON_UNAVAILABLE_NONE" 0 "SMART_SUMMON_UNAVAILABLE_UNKNOWN" ;
VAL_ 601 APP_fsdSuspendState 3 "SNA" 1 "SUSPENDED" 0 "NOT_SUSPENDED" ;
VAL_ 601 APP_fsdRevokeStrikeoutCount 7 "SNA" ;
VAL_ 601 APP_teslaVisionSupported 3 "SNA" 1 "SUPPORTED" 0 "NOT_SUPPORTED" ;
VAL_ 601 APP_teslaVisionUnsupportedReason 4 "VEHICLE_LOCATION" 3 "UNSUPPORTED_CAMERA" 2 "AP_HARDWARE" 1 "NONE" 0 "UNKNOWN" ;
VAL_ 601 APP_fsdRevokeCount 7 "SNA" ;
VAL_ 601 APP_unifiedObjectStackSupported 3 "SNA" 1 "SUPPORTED" 0 "NOT_SUPPORTED" ;
VAL_ 601 APP_DDAWSystemStatus 4 "DDAW_SYSTEM_SNA" 3 "DDAW_SYSTEM_INVALID" 2 "DDAW_SYSTEM_FAILURE" 1 "DDAW_SYSTEM_DRIVER_DROWSY" 0 "DDAW_SYSTEM_NOMINAL" ;
VAL_ 601 APP_socOperatingMode 2 "AP_DUAL_SOC" 1 "AP_SINGLE_SOC" 0 "AP_UNKNOWN" ;
VAL_ 601 APP_summonVersionIdentifier 2 "AUTONOMY_SUMMON" 1 "ACTUALLY_SMART_SUMMON" 0 "LEGACY_SMART_SUMMON" ;
VAL_ 601 APP_sentryState 6 "SENTRY_SNA" 5 "SENTRY_QUIET" 4 "SENTRY_PANIC" 3 "SENTRY_AWARE" 2 "SENTRY_ARMED" 1 "SENTRY_IDLE" 0 "SENTRY_OFF" ;
VAL_ 601 APP_autoparkVersionIdentifier 2 "ACTUALLY_SMART_AUTOPARK" 1 "V3_VISION_AUTOPARK" 0 "LEGACY_AUTOPARK" ;
VAL_ 601 APP_autonomySystemHealth 1 "AUTONOMY_SYSTEM_HEALTH_HEALTHY" 0 "AUTONOMY_SYSTEM_HEALTH_UNHEALTHY" ;
VAL_ 605 APP_tcFeatureState 3 "TC_ACTIVE" 2 "TC_AVAILABLE" 1 "TC_UNAVAILABLE" 0 "TC_DISABLED" ;
VAL_ 605 APP_tcStateMachine 6 "TCSM_CONTINUING" 5 "TCSM_STOPPED" 4 "TCSM_STOPPING" 3 "TCSM_WARNING" 2 "TCSM_AWARE" 1 "TCSM_STANDBY" 0 "TCSM_DISABLED" ;
VAL_ 605 APP_tcControlSource 3 "TC_SOURCE_MAP_AND_VISION" 2 "TC_SOURCE_VISION" 1 "TC_SOURCE_MAP" 0 "TC_SOURCE_NONE" ;
VAL_ 605 APP_tcControlType 22 "TC_TYPE_T_ARM" 21 "TC_TYPE_BEV_JUNCTION" 20 "TC_TYPE_T_IMPLICIT_BY_GEOM" 19 "TC_TYPE_T_IMPLICIT_BY_NAME" 18 "TC_TYPE_T_IMPLICIT" 17 "TC_TYPE_NO_STOP" 16 "TC_TYPE_BIKE_MERGE_FROM_RIGHT" 15 "TC_TYPE_BIKE_MERGE_FROM_LEFT" 14 "TC_TYPE_ALL_WAY_STOP_SIGN" 13 "TC_TYPE_TRAFFIC_RULE" 12 "TC_TYPE_SPEED_HUMP" 11 "TC_TYPE_SPEED_BUMP" 10 "TC_TYPE_RAMP_METER" 9 "TC_TYPE_PEDESTRIAN_CROSSING" 8 "TC_TYPE_SUICIDE_LEFT" 7 "TC_TYPE_KEEP_CLEAR_EXIT" 6 "TC_TYPE_KEEP_CLEAR_ENTER" 5 "TC_TYPE_CROSSWALK" 4 "TC_TYPE_YIELD" 3 "TC_TYPE_TRAFFIC_LIGHT" 2 "TC_TYPE_STOP_SIGN" 1 "TC_TYPE_UNKNOWN" 0 "TC_TYPE_INVALID" ;
VAL_ 605 APP_tcControlDistance 255 "SNA" ;
VAL_ 605 APP_tcControlLightState 6 "TC_LIGHTSTATE_OTHER" 5 "TC_LIGHTSTAET_WHITE" 4 "TC_LIGHTSTATE_OFF" 3 "TC_LIGHTSTATE_YELLOW" 2 "TC_LIGHTSTATE_GREEN" 1 "TC_LIGHTSTATE_RED" 0 "TC_LIGHTSTATE_NONE" ;
VAL_ 605 APP_tcContinuationReason 13 "TC_CONTINUE_CONTROL_UNAVAILABLE" 12 "TC_CONTINUE_SUMMON_TIMEOUT" 11 "TC_CONTINUE_CLEAR_TO_GO" 10 "TC_CONTINUE_WARNING_TIMEOUT" 9 "TC_CONTINUE_INVALID_MAP_OR_VISION_CONTROL" 8 "TC_CONTINUE_PASSED_STOP" 7 "TC_CONTINUE_ASSUMED_DRIVER_STOPPED" 6 "TC_CONTINUE_AP_ACTIVATED_ON_HARD_STOP" 5 "TC_CONTINUE_VISION_SIGNALS" 4 "TC_CONTINUE_REQUIRED_DECEL_TOO_HIGH" 3 "TC_CONTINUE_USER_INPUT_ON_RED" 2 "TC_CONTINUE_USER_INPUT_ON_GREEN" 1 "TC_CONTINUE_GREEN_LIGHT_WITH_CIPV" 0 "TC_CONTINUE_NONE" ;
VAL_ 605 APP_tcConfirmationType 2 "TC_CONFIRM_PEDAL" 1 "TC_CONFIRM_STALK" 0 "TC_CONFIRM_NONE" ;
VAL_ 605 APP_tcWarningSuppressionReason 18 "TC_WARNING_SUPPRESS_TOO_FAR_FROM_PREDICTED_JUNCTION" 17 "TC_WARNING_SUPPRESS_NOT_SUPPORTED_BY_MEASUREMENTS" 16 "TC_WARNING_SUPPRESS_NO_ASSOCIATED_VISION_LINE" 15 "TC_WARNING_SUPPRESS_AMBIGUOUS_VISION_TYPE" 14 "TC_WARNING_SUPPRESS_CIPV_DID_NOT_STOP" 13 "TC_WARNING_SUPPRESS_STALE_SIGN_DETECTION" 12 "TC_WARNING_SUPPRESS_WRONG_MAP_TYPE" 11 "TC_WARNING_SUPPRESS_LIGHT_UNASSOCIATED" 10 "TC_WARNING_SUPPRESS_CIPV_CONTINUING" 9 "TC_WARNING_SUPPRESS_PEDAL_OVERRIDE" 8 "TC_WARNING_SUPPRESS_LOCALIZATION_DEGRADED" 7 "TC_WARNING_SUPPRESS_HARD_TURN" 6 "TC_WARNING_SUPPRESS_ASSUMED_YELLOW" 5 "TC_WARNING_SUPPRESS_DRIVER_SLOWING_DOWN" 4 "TC_WARNING_SUPPRESS_BELOW_MIN_SPEED" 3 "TC_WARNING_SUPPRESS_SLOWDOWN_PLANNED" 2 "TC_WARNING_SUPPRESS_INSUFFICIENT_DATA" 1 "TC_WARNING_SUPPRESS_FEATURE_DISABLED" 0 "TC_WARNING_SUPPRESS_NONE" ;
VAL_ 605 APP_tcUnavailableReason 9 "AP_UNAVAILBLE_SUN_GLARE_ON_ROAD_RESTRICTED" 8 "AP_UNAVAILBLE_CAMERA_BLINDED_ON_ROAD_RESTRICTED" 7 "AP_UNAVAILBLE_GPS_DEGRADED" 6 "AP_UNAVAILBLE_ROAD_ESTIMATOR_UNHEALTHY" 5 "AP_UNAVAILBLE_SUN_GLARE" 4 "AP_UNAVAILBLE_CAMERA_BLINDED" 3 "AP_UNAVAILBLE_ROAD_CLASS" 2 "AP_UNAVAILBLE_LOST_MAP_LOCALIZATION" 1 "AP_UNAVAILBLE_MCU_DISABLED" 0 "AP_UNAVAILBLE_NONE" ;
VAL_ 859 APP_visionOcsStateRaw 3 "ADULT" 2 "CHILD" 1 "EMPTY" 0 "UNKNOWN" ;
VAL_ 859 APP_visionOcsEmptyProbRaw 255 "SNA" ;
VAL_ 859 APP_visionOcsChildProbRaw 255 "SNA" ;
VAL_ 859 APP_visionOcsAdultProbRaw 255 "SNA" ;
VAL_ 859 APP_visionOcsFrontPasClsVisionSt 3 "ADULT" 2 "CHILD" 1 "EMPTY" 0 "UNKNOWN" ;
